VERSION "dbc-export 1 2026.26.6.5"

NS_ :

BS_:

BU_: ADSP APB APP APS APSB BB BMS CC CMP CMPD CP DAS DI DIF DIR DPB EPAS3P EPAS3S EPASTP EPASTS EPBL EPBR ESP EVSE FC GTW HCML HCMR HVP IBST ICR IDB LS OCS1P PARK PCS PCS2 PM PMF PMR PNCD PTC RADC RCM RCM2 RCM3 RCU SCCM SCM SCS SDCR TAS TCU TCU2 TPMS TRCM UI UIS UMC USM V2G VC VCBATT VCBATT0 VCBATT1 VCBATT2 VCCC VCFRONT VCFRONT1 VCFRONT2 VCLEFT VCRIGHT VCSEAT2L VCSEAT2R VCSEC VEH

BO_ 1486 PARK_alertLog: 8 PARK
 SG_ PARK_alertID M : 0|7@1+ (1,0) [0|127] "" Vector__XXX
 SG_ PARK_alertState : 15|1@1+ (1,0) [0|1] "" Vector__XXX
 SG_ PARK_sw001_sensorTemperature m1 : 16|16@1+ (0.1,-40) [-40|6513.5] "" Vector__XXX
 SG_ PARK_sw002_membraneDisconct m2 : 16|1@1+ (1,0) [0|1] "" Vector__XXX
 SG_ PARK_sw002_dampResistorFail m2 : 17|1@1+ (1,0) [0|1] "" Vector__XXX
 SG_ PARK_sw002_resonanceDrift m2 : 18|1@1+ (1,0) [0|1] "" Vector__XXX
 SG_ PARK_sw002_sensorCRC m2 : 19|1@1+ (1,0) [0|1] "" Vector__XXX
 SG_ PARK_sw002_recieveFailure m2 : 20|1@1+ (1,0) [0|1] "" Vector__XXX
 SG_ PARK_sw002_diagnosticTransferErr m2 : 21|1@1+ (1,0) [0|1] "" Vector__XXX
 SG_ PARK_sw003_linError m3 : 16|1@1+ (1,0) [0|1] "" Vector__XXX
 SG_ PARK_sw003_linBusError m3 : 17|1@1+ (1,0) [0|1] "" Vector__XXX
 SG_ PARK_sw003_linFrameCountError m3 : 18|1@1+ (1,0) [0|1] "" Vector__XXX
 SG_ PARK_sw004_reverbPeriod m4 : 16|16@1+ (1,0) [0|65535] "" Vector__XXX
 SG_ PARK_sw004_reverbTime m4 : 32|16@1+ (1,0) [0|65535] "" Vector__XXX
 SG_ PARK_sw004_highAttenTime m4 : 48|1@1+ (1,0) [0|1] "" Vector__XXX
 SG_ PARK_sw004_closeConstEcho m4 : 49|1@1+ (1,0) [0|1] "" Vector__XXX
 SG_ PARK_sw004_lowAttenTime m4 : 50|1@1+ (1,0) [0|1] "" Vector__XXX
 SG_ PARK_sw004_attenTimeJitter m4 : 51|1@1+ (1,0) [0|1] "" Vector__XXX
 SG_ PARK_sw004_reverbFreqJitter m4 : 52|1@1+ (1,0) [0|1] "" Vector__XXX
 SG_ PARK_sw006_sensorTemperature m6 : 16|16@1+ (0.1,-40) [-40|6513.5] "" Vector__XXX
 SG_ PARK_sw007_membraneDisconct m7 : 16|1@1+ (1,0) [0|1] "" Vector__XXX
 SG_ PARK_sw007_dampResistorFail m7 : 17|1@1+ (1,0) [0|1] "" Vector__XXX
 SG_ PARK_sw007_resonanceDrift m7 : 18|1@1+ (1,0) [0|1] "" Vector__XXX
 SG_ PARK_sw007_sensorCRC m7 : 19|1@1+ (1,0) [0|1] "" Vector__XXX
 SG_ PARK_sw007_recieveFailure m7 : 20|1@1+ (1,0) [0|1] "" Vector__XXX
 SG_ PARK_sw007_diagnosticTransferErr m7 : 21|1@1+ (1,0) [0|1] "" Vector__XXX
 SG_ PARK_sw008_linError m8 : 16|1@1+ (1,0) [0|1] "" Vector__XXX
 SG_ PARK_sw008_linBusError m8 : 17|1@1+ (1,0) [0|1] "" Vector__XXX
 SG_ PARK_sw008_linFrameCountError m8 : 18|1@1+ (1,0) [0|1] "" Vector__XXX
 SG_ PARK_sw009_reverbPeriod m9 : 16|16@1+ (1,0) [0|65535] "" Vector__XXX
 SG_ PARK_sw009_reverbTime m9 : 32|16@1+ (1,0) [0|65535] "" Vector__XXX
 SG_ PARK_sw009_highAttenTime m9 : 48|1@1+ (1,0) [0|1] "" Vector__XXX
 SG_ PARK_sw009_closeConstEcho m9 : 49|1@1+ (1,0) [0|1] "" Vector__XXX
 SG_ PARK_sw009_lowAttenTime m9 : 50|1@1+ (1,0) [0|1] "" Vector__XXX
 SG_ PARK_sw009_attenTimeJitter m9 : 51|1@1+ (1,0) [0|1] "" Vector__XXX
 SG_ PARK_sw009_reverbFreqJitter m9 : 52|1@1+ (1,0) [0|1] "" Vector__XXX
 SG_ PARK_sw011_sensorTemperature m11 : 16|16@1+ (0.1,-40) [-40|6513.5] "" Vector__XXX
 SG_ PARK_sw012_membraneDisconct m12 : 16|1@1+ (1,0) [0|1] "" Vector__XXX
 SG_ PARK_sw012_dampResistorFail m12 : 17|1@1+ (1,0) [0|1] "" Vector__XXX
 SG_ PARK_sw012_resonanceDrift m12 : 18|1@1+ (1,0) [0|1] "" Vector__XXX
 SG_ PARK_sw012_sensorCRC m12 : 19|1@1+ (1,0) [0|1] "" Vector__XXX
 SG_ PARK_sw012_recieveFailure m12 : 20|1@1+ (1,0) [0|1] "" Vector__XXX
 SG_ PARK_sw012_diagnosticTransferErr m12 : 21|1@1+ (1,0) [0|1] "" Vector__XXX
 SG_ PARK_sw013_linError m13 : 16|1@1+ (1,0) [0|1] "" Vector__XXX
 SG_ PARK_sw013_linBusError m13 : 17|1@1+ (1,0) [0|1] "" Vector__XXX
 SG_ PARK_sw013_linFrameCountError m13 : 18|1@1+ (1,0) [0|1] "" Vector__XXX
 SG_ PARK_sw014_reverbPeriod m14 : 16|16@1+ (1,0) [0|65535] "" Vector__XXX
 SG_ PARK_sw014_reverbTime m14 : 32|16@1+ (1,0) [0|65535] "" Vector__XXX
 SG_ PARK_sw014_highAttenTime m14 : 48|1@1+ (1,0) [0|1] "" Vector__XXX
 SG_ PARK_sw014_closeConstEcho m14 : 49|1@1+ (1,0) [0|1] "" Vector__XXX
 SG_ PARK_sw014_lowAttenTime m14 : 50|1@1+ (1,0) [0|1] "" Vector__XXX
 SG_ PARK_sw014_attenTimeJitter m14 : 51|1@1+ (1,0) [0|1] "" Vector__XXX
 SG_ PARK_sw014_reverbFreqJitter m14 : 52|1@1+ (1,0) [0|1] "" Vector__XXX
 SG_ PARK_sw016_sensorTemperature m16 : 16|16@1+ (0.1,-40) [-40|6513.5] "" Vector__XXX
 SG_ PARK_sw017_membraneDisconct m17 : 16|1@1+ (1,0) [0|1] "" Vector__XXX
 SG_ PARK_sw017_dampResistorFail m17 : 17|1@1+ (1,0) [0|1] "" Vector__XXX
 SG_ PARK_sw017_resonanceDrift m17 : 18|1@1+ (1,0) [0|1] "" Vector__XXX
 SG_ PARK_sw017_sensorCRC m17 : 19|1@1+ (1,0) [0|1] "" Vector__XXX
 SG_ PARK_sw017_recieveFailure m17 : 20|1@1+ (1,0) [0|1] "" Vector__XXX
 SG_ PARK_sw017_diagnosticTransferErr m17 : 21|1@1+ (1,0) [0|1] "" Vector__XXX
 SG_ PARK_sw018_linError m18 : 16|1@1+ (1,0) [0|1] "" Vector__XXX
 SG_ PARK_sw018_linBusError m18 : 17|1@1+ (1,0) [0|1] "" Vector__XXX
 SG_ PARK_sw018_linFrameCountError m18 : 18|1@1+ (1,0) [0|1] "" Vector__XXX
 SG_ PARK_sw019_reverbPeriod m19 : 16|16@1+ (1,0) [0|65535] "" Vector__XXX
 SG_ PARK_sw019_reverbTime m19 : 32|16@1+ (1,0) [0|65535] "" Vector__XXX
 SG_ PARK_sw019_highAttenTime m19 : 48|1@1+ (1,0) [0|1] "" Vector__XXX
 SG_ PARK_sw019_closeConstEcho m19 : 49|1@1+ (1,0) [0|1] "" Vector__XXX
 SG_ PARK_sw019_lowAttenTime m19 : 50|1@1+ (1,0) [0|1] "" Vector__XXX
 SG_ PARK_sw019_attenTimeJitter m19 : 51|1@1+ (1,0) [0|1] "" Vector__XXX
 SG_ PARK_sw019_reverbFreqJitter m19 : 52|1@1+ (1,0) [0|1] "" Vector__XXX
 SG_ PARK_sw021_sensorTemperature m21 : 16|16@1+ (0.1,-40) [-40|6513.5] "" Vector__XXX
 SG_ PARK_sw022_membraneDisconct m22 : 16|1@1+ (1,0) [0|1] "" Vector__XXX
 SG_ PARK_sw022_dampResistorFail m22 : 17|1@1+ (1,0) [0|1] "" Vector__XXX
 SG_ PARK_sw022_resonanceDrift m22 : 18|1@1+ (1,0) [0|1] "" Vector__XXX
 SG_ PARK_sw022_sensorCRC m22 : 19|1@1+ (1,0) [0|1] "" Vector__XXX
 SG_ PARK_sw022_recieveFailure m22 : 20|1@1+ (1,0) [0|1] "" Vector__XXX
 SG_ PARK_sw022_diagnosticTransferErr m22 : 21|1@1+ (1,0) [0|1] "" Vector__XXX
 SG_ PARK_sw023_linError m23 : 16|1@1+ (1,0) [0|1] "" Vector__XXX
 SG_ PARK_sw023_linBusError m23 : 17|1@1+ (1,0) [0|1] "" Vector__XXX
 SG_ PARK_sw023_linFrameCountError m23 : 18|1@1+ (1,0) [0|1] "" Vector__XXX
 SG_ PARK_sw024_reverbPeriod m24 : 16|16@1+ (1,0) [0|65535] "" Vector__XXX
 SG_ PARK_sw024_reverbTime m24 : 32|16@1+ (1,0) [0|65535] "" Vector__XXX
 SG_ PARK_sw024_highAttenTime m24 : 48|1@1+ (1,0) [0|1] "" Vector__XXX
 SG_ PARK_sw024_closeConstEcho m24 : 49|1@1+ (1,0) [0|1] "" Vector__XXX
 SG_ PARK_sw024_lowAttenTime m24 : 50|1@1+ (1,0) [0|1] "" Vector__XXX
 SG_ PARK_sw024_attenTimeJitter m24 : 51|1@1+ (1,0) [0|1] "" Vector__XXX
 SG_ PARK_sw024_reverbFreqJitter m24 : 52|1@1+ (1,0) [0|1] "" Vector__XXX
 SG_ PARK_sw026_sensorTemperature m26 : 16|16@1+ (0.1,-40) [-40|6513.5] "" Vector__XXX
 SG_ PARK_sw027_membraneDisconct m27 : 16|1@1+ (1,0) [0|1] "" Vector__XXX
 SG_ PARK_sw027_dampResistorFail m27 : 17|1@1+ (1,0) [0|1] "" Vector__XXX
 SG_ PARK_sw027_resonanceDrift m27 : 18|1@1+ (1,0) [0|1] "" Vector__XXX
 SG_ PARK_sw027_sensorCRC m27 : 19|1@1+ (1,0) [0|1] "" Vector__XXX
 SG_ PARK_sw027_recieveFailure m27 : 20|1@1+ (1,0) [0|1] "" Vector__XXX
 SG_ PARK_sw027_diagnosticTransferErr m27 : 21|1@1+ (1,0) [0|1] "" Vector__XXX
 SG_ PARK_sw028_linError m28 : 16|1@1+ (1,0) [0|1] "" Vector__XXX
 SG_ PARK_sw028_linBusError m28 : 17|1@1+ (1,0) [0|1] "" Vector__XXX
 SG_ PARK_sw028_linFrameCountError m28 : 18|1@1+ (1,0) [0|1] "" Vector__XXX
 SG_ PARK_sw029_reverbPeriod m29 : 16|16@1+ (1,0) [0|65535] "" Vector__XXX
 SG_ PARK_sw029_reverbTime m29 : 32|16@1+ (1,0) [0|65535] "" Vector__XXX
 SG_ PARK_sw029_highAttenTime m29 : 48|1@1+ (1,0) [0|1] "" Vector__XXX
 SG_ PARK_sw029_closeConstEcho m29 : 49|1@1+ (1,0) [0|1] "" Vector__XXX
 SG_ PARK_sw029_lowAttenTime m29 : 50|1@1+ (1,0) [0|1] "" Vector__XXX
 SG_ PARK_sw029_attenTimeJitter m29 : 51|1@1+ (1,0) [0|1] "" Vector__XXX
 SG_ PARK_sw029_reverbFreqJitter m29 : 52|1@1+ (1,0) [0|1] "" Vector__XXX
 SG_ PARK_sw031_sensorTemperature m31 : 16|16@1+ (0.1,-40) [-40|6513.5] "" Vector__XXX
 SG_ PARK_sw032_membraneDisconct m32 : 16|1@1+ (1,0) [0|1] "" Vector__XXX
 SG_ PARK_sw032_dampResistorFail m32 : 17|1@1+ (1,0) [0|1] "" Vector__XXX
 SG_ PARK_sw032_resonanceDrift m32 : 18|1@1+ (1,0) [0|1] "" Vector__XXX
 SG_ PARK_sw032_sensorCRC m32 : 19|1@1+ (1,0) [0|1] "" Vector__XXX
 SG_ PARK_sw032_recieveFailure m32 : 20|1@1+ (1,0) [0|1] "" Vector__XXX
 SG_ PARK_sw032_diagnosticTransferErr m32 : 21|1@1+ (1,0) [0|1] "" Vector__XXX
 SG_ PARK_sw033_linError m33 : 16|1@1+ (1,0) [0|1] "" Vector__XXX
 SG_ PARK_sw033_linBusError m33 : 17|1@1+ (1,0) [0|1] "" Vector__XXX
 SG_ PARK_sw033_linFrameCountError m33 : 18|1@1+ (1,0) [0|1] "" Vector__XXX
 SG_ PARK_sw034_reverbPeriod m34 : 16|16@1+ (1,0) [0|65535] "" Vector__XXX
 SG_ PARK_sw034_reverbTime m34 : 32|16@1+ (1,0) [0|65535] "" Vector__XXX
 SG_ PARK_sw034_highAttenTime m34 : 48|1@1+ (1,0) [0|1] "" Vector__XXX
 SG_ PARK_sw034_closeConstEcho m34 : 49|1@1+ (1,0) [0|1] "" Vector__XXX
 SG_ PARK_sw034_lowAttenTime m34 : 50|1@1+ (1,0) [0|1] "" Vector__XXX
 SG_ PARK_sw034_attenTimeJitter m34 : 51|1@1+ (1,0) [0|1] "" Vector__XXX
 SG_ PARK_sw034_reverbFreqJitter m34 : 52|1@1+ (1,0) [0|1] "" Vector__XXX
 SG_ PARK_sw036_sensorTemperature m36 : 16|16@1+ (0.1,-40) [-40|6513.5] "" Vector__XXX
 SG_ PARK_sw037_membraneDisconct m37 : 16|1@1+ (1,0) [0|1] "" Vector__XXX
 SG_ PARK_sw037_dampResistorFail m37 : 17|1@1+ (1,0) [0|1] "" Vector__XXX
 SG_ PARK_sw037_resonanceDrift m37 : 18|1@1+ (1,0) [0|1] "" Vector__XXX
 SG_ PARK_sw037_sensorCRC m37 : 19|1@1+ (1,0) [0|1] "" Vector__XXX
 SG_ PARK_sw037_recieveFailure m37 : 20|1@1+ (1,0) [0|1] "" Vector__XXX
 SG_ PARK_sw037_diagnosticTransferErr m37 : 21|1@1+ (1,0) [0|1] "" Vector__XXX
 SG_ PARK_sw038_linError m38 : 16|1@1+ (1,0) [0|1] "" Vector__XXX
 SG_ PARK_sw038_linBusError m38 : 17|1@1+ (1,0) [0|1] "" Vector__XXX
 SG_ PARK_sw038_linFrameCountError m38 : 18|1@1+ (1,0) [0|1] "" Vector__XXX
 SG_ PARK_sw039_reverbPeriod m39 : 16|16@1+ (1,0) [0|65535] "" Vector__XXX
 SG_ PARK_sw039_reverbTime m39 : 32|16@1+ (1,0) [0|65535] "" Vector__XXX
 SG_ PARK_sw039_highAttenTime m39 : 48|1@1+ (1,0) [0|1] "" Vector__XXX
 SG_ PARK_sw039_closeConstEcho m39 : 49|1@1+ (1,0) [0|1] "" Vector__XXX
 SG_ PARK_sw039_lowAttenTime m39 : 50|1@1+ (1,0) [0|1] "" Vector__XXX
 SG_ PARK_sw039_attenTimeJitter m39 : 51|1@1+ (1,0) [0|1] "" Vector__XXX
 SG_ PARK_sw039_reverbFreqJitter m39 : 52|1@1+ (1,0) [0|1] "" Vector__XXX
 SG_ PARK_sw041_sensorTemperature m41 : 16|16@1+ (0.1,-40) [-40|6513.5] "" Vector__XXX
 SG_ PARK_sw042_membraneDisconct m42 : 16|1@1+ (1,0) [0|1] "" Vector__XXX
 SG_ PARK_sw042_dampResistorFail m42 : 17|1@1+ (1,0) [0|1] "" Vector__XXX
 SG_ PARK_sw042_resonanceDrift m42 : 18|1@1+ (1,0) [0|1] "" Vector__XXX
 SG_ PARK_sw042_sensorCRC m42 : 19|1@1+ (1,0) [0|1] "" Vector__XXX
 SG_ PARK_sw042_recieveFailure m42 : 20|1@1+ (1,0) [0|1] "" Vector__XXX
 SG_ PARK_sw042_diagnosticTransferErr m42 : 21|1@1+ (1,0) [0|1] "" Vector__XXX
 SG_ PARK_sw043_linError m43 : 16|1@1+ (1,0) [0|1] "" Vector__XXX
 SG_ PARK_sw043_linBusError m43 : 17|1@1+ (1,0) [0|1] "" Vector__XXX
 SG_ PARK_sw043_linFrameCountError m43 : 18|1@1+ (1,0) [0|1] "" Vector__XXX
 SG_ PARK_sw044_reverbPeriod m44 : 16|16@1+ (1,0) [0|65535] "" Vector__XXX
 SG_ PARK_sw044_reverbTime m44 : 32|16@1+ (1,0) [0|65535] "" Vector__XXX
 SG_ PARK_sw044_highAttenTime m44 : 48|1@1+ (1,0) [0|1] "" Vector__XXX
 SG_ PARK_sw044_closeConstEcho m44 : 49|1@1+ (1,0) [0|1] "" Vector__XXX
 SG_ PARK_sw044_lowAttenTime m44 : 50|1@1+ (1,0) [0|1] "" Vector__XXX
 SG_ PARK_sw044_attenTimeJitter m44 : 51|1@1+ (1,0) [0|1] "" Vector__XXX
 SG_ PARK_sw044_reverbFreqJitter m44 : 52|1@1+ (1,0) [0|1] "" Vector__XXX
 SG_ PARK_sw046_sensorTemperature m46 : 16|16@1+ (0.1,-40) [-40|6513.5] "" Vector__XXX
 SG_ PARK_sw047_membraneDisconct m47 : 16|1@1+ (1,0) [0|1] "" Vector__XXX
 SG_ PARK_sw047_dampResistorFail m47 : 17|1@1+ (1,0) [0|1] "" Vector__XXX
 SG_ PARK_sw047_resonanceDrift m47 : 18|1@1+ (1,0) [0|1] "" Vector__XXX
 SG_ PARK_sw047_sensorCRC m47 : 19|1@1+ (1,0) [0|1] "" Vector__XXX
 SG_ PARK_sw047_recieveFailure m47 : 20|1@1+ (1,0) [0|1] "" Vector__XXX
 SG_ PARK_sw047_diagnosticTransferErr m47 : 21|1@1+ (1,0) [0|1] "" Vector__XXX
 SG_ PARK_sw048_linError m48 : 16|1@1+ (1,0) [0|1] "" Vector__XXX
 SG_ PARK_sw048_linBusError m48 : 17|1@1+ (1,0) [0|1] "" Vector__XXX
 SG_ PARK_sw048_linFrameCountError m48 : 18|1@1+ (1,0) [0|1] "" Vector__XXX
 SG_ PARK_sw049_reverbPeriod m49 : 16|16@1+ (1,0) [0|65535] "" Vector__XXX
 SG_ PARK_sw049_reverbTime m49 : 32|16@1+ (1,0) [0|65535] "" Vector__XXX
 SG_ PARK_sw049_highAttenTime m49 : 48|1@1+ (1,0) [0|1] "" Vector__XXX
 SG_ PARK_sw049_closeConstEcho m49 : 49|1@1+ (1,0) [0|1] "" Vector__XXX
 SG_ PARK_sw049_lowAttenTime m49 : 50|1@1+ (1,0) [0|1] "" Vector__XXX
 SG_ PARK_sw049_attenTimeJitter m49 : 51|1@1+ (1,0) [0|1] "" Vector__XXX
 SG_ PARK_sw049_reverbFreqJitter m49 : 52|1@1+ (1,0) [0|1] "" Vector__XXX
 SG_ PARK_sw051_sensorTemperature m51 : 16|16@1+ (0.1,-40) [-40|6513.5] "" Vector__XXX
 SG_ PARK_sw052_membraneDisconct m52 : 16|1@1+ (1,0) [0|1] "" Vector__XXX
 SG_ PARK_sw052_dampResistorFail m52 : 17|1@1+ (1,0) [0|1] "" Vector__XXX
 SG_ PARK_sw052_resonanceDrift m52 : 18|1@1+ (1,0) [0|1] "" Vector__XXX
 SG_ PARK_sw052_sensorCRC m52 : 19|1@1+ (1,0) [0|1] "" Vector__XXX
 SG_ PARK_sw052_recieveFailure m52 : 20|1@1+ (1,0) [0|1] "" Vector__XXX
 SG_ PARK_sw052_diagnosticTransferErr m52 : 21|1@1+ (1,0) [0|1] "" Vector__XXX
 SG_ PARK_sw053_linError m53 : 16|1@1+ (1,0) [0|1] "" Vector__XXX
 SG_ PARK_sw053_linBusError m53 : 17|1@1+ (1,0) [0|1] "" Vector__XXX
 SG_ PARK_sw053_linFrameCountError m53 : 18|1@1+ (1,0) [0|1] "" Vector__XXX
 SG_ PARK_sw054_reverbPeriod m54 : 16|16@1+ (1,0) [0|65535] "" Vector__XXX
 SG_ PARK_sw054_reverbTime m54 : 32|16@1+ (1,0) [0|65535] "" Vector__XXX
 SG_ PARK_sw054_highAttenTime m54 : 48|1@1+ (1,0) [0|1] "" Vector__XXX
 SG_ PARK_sw054_closeConstEcho m54 : 49|1@1+ (1,0) [0|1] "" Vector__XXX
 SG_ PARK_sw054_lowAttenTime m54 : 50|1@1+ (1,0) [0|1] "" Vector__XXX
 SG_ PARK_sw054_attenTimeJitter m54 : 51|1@1+ (1,0) [0|1] "" Vector__XXX
 SG_ PARK_sw054_reverbFreqJitter m54 : 52|1@1+ (1,0) [0|1] "" Vector__XXX
 SG_ PARK_sw056_sensorTemperature m56 : 16|16@1+ (0.1,-40) [-40|6513.5] "" Vector__XXX
 SG_ PARK_sw057_membraneDisconct m57 : 16|1@1+ (1,0) [0|1] "" Vector__XXX
 SG_ PARK_sw057_dampResistorFail m57 : 17|1@1+ (1,0) [0|1] "" Vector__XXX
 SG_ PARK_sw057_resonanceDrift m57 : 18|1@1+ (1,0) [0|1] "" Vector__XXX
 SG_ PARK_sw057_sensorCRC m57 : 19|1@1+ (1,0) [0|1] "" Vector__XXX
 SG_ PARK_sw057_recieveFailure m57 : 20|1@1+ (1,0) [0|1] "" Vector__XXX
 SG_ PARK_sw057_diagnosticTransferErr m57 : 21|1@1+ (1,0) [0|1] "" Vector__XXX
 SG_ PARK_sw058_linError m58 : 16|1@1+ (1,0) [0|1] "" Vector__XXX
 SG_ PARK_sw058_linBusError m58 : 17|1@1+ (1,0) [0|1] "" Vector__XXX
 SG_ PARK_sw058_linFrameCountError m58 : 18|1@1+ (1,0) [0|1] "" Vector__XXX
 SG_ PARK_sw059_reverbPeriod m59 : 16|16@1+ (1,0) [0|65535] "" Vector__XXX
 SG_ PARK_sw059_reverbTime m59 : 32|16@1+ (1,0) [0|65535] "" Vector__XXX
 SG_ PARK_sw059_highAttenTime m59 : 48|1@1+ (1,0) [0|1] "" Vector__XXX
 SG_ PARK_sw059_closeConstEcho m59 : 49|1@1+ (1,0) [0|1] "" Vector__XXX
 SG_ PARK_sw059_lowAttenTime m59 : 50|1@1+ (1,0) [0|1] "" Vector__XXX
 SG_ PARK_sw059_attenTimeJitter m59 : 51|1@1+ (1,0) [0|1] "" Vector__XXX
 SG_ PARK_sw059_reverbFreqJitter m59 : 52|1@1+ (1,0) [0|1] "" Vector__XXX
 SG_ PARK_sw061_voltage m61 : 16|16@1+ (0.1,0) [0|6553.5] "" Vector__XXX
 SG_ PARK_sw063_voltage m63 : 16|16@1+ (0.1,0) [0|6553.5] "" Vector__XXX
 SG_ PARK_sw064_faultCode m64 : 16|8@1+ (1,0) [0|255] "" Vector__XXX
 SG_ PARK_sw065_expectedCRC m65 : 16|16@1+ (1,0) [0|65535] "" Vector__XXX
 SG_ PARK_sw065_calculatedCRC m65 : 32|16@1+ (1,0) [0|65535] "" Vector__XXX
 SG_ PARK_sw066_placeHolder m66 : 16|1@1+ (1,0) [0|1] "" Vector__XXX
 SG_ PARK_sw068_placeHolder m68 : 16|1@1+ (1,0) [0|1] "" Vector__XXX
 SG_ PARK_sw069_messageID m69 : 16|16@1+ (1,0) [0|65535] "" Vector__XXX
 SG_ PARK_sw070_messageID m70 : 16|16@1+ (1,0) [0|65535] "" Vector__XXX
 SG_ PARK_sw071_messageID m71 : 16|16@1+ (1,0) [0|65535] "" Vector__XXX
 SG_ PARK_sw072_messageID m72 : 16|16@1+ (1,0) [0|65535] "" Vector__XXX
 SG_ PARK_sw073_messageID m73 : 16|16@1+ (1,0) [0|65535] "" Vector__XXX
 SG_ PARK_sw074_messageID m74 : 16|16@1+ (1,0) [0|65535] "" Vector__XXX
 SG_ PARK_sw075_messageID m75 : 16|16@1+ (1,0) [0|65535] "" Vector__XXX
 SG_ PARK_sw076_messageID m76 : 16|16@1+ (1,0) [0|65535] "" Vector__XXX
 SG_ PARK_sw077_errorExp m77 : 16|8@1+ (1,0) [0|255] "" Vector__XXX
 SG_ PARK_sw077_errorRx m77 : 24|8@1+ (1,0) [0|255] "" Vector__XXX
 SG_ PARK_sw077_messageID m77 : 32|12@1+ (1,0) [0|4095] "" Vector__XXX
 SG_ PARK_sw077_errorType m77 : 44|3@1+ (1,0) [0|7] "" Vector__XXX
 SG_ PARK_sw078_errorExp m78 : 16|8@1+ (1,0) [0|255] "" Vector__XXX
 SG_ PARK_sw078_errorRx m78 : 24|8@1+ (1,0) [0|255] "" Vector__XXX
 SG_ PARK_sw078_messageID m78 : 32|12@1+ (1,0) [0|4095] "" Vector__XXX
 SG_ PARK_sw078_errorType m78 : 44|3@1+ (1,0) [0|7] "" Vector__XXX
 SG_ PARK_sw079_errorExp m79 : 16|8@1+ (1,0) [0|255] "" Vector__XXX
 SG_ PARK_sw079_errorRx m79 : 24|8@1+ (1,0) [0|255] "" Vector__XXX
 SG_ PARK_sw079_messageID m79 : 32|12@1+ (1,0) [0|4095] "" Vector__XXX
 SG_ PARK_sw079_errorType m79 : 44|3@1+ (1,0) [0|7] "" Vector__XXX
 SG_ PARK_sw080_errorExp m80 : 16|8@1+ (1,0) [0|255] "" Vector__XXX
 SG_ PARK_sw080_errorRx m80 : 24|8@1+ (1,0) [0|255] "" Vector__XXX
 SG_ PARK_sw080_messageID m80 : 32|12@1+ (1,0) [0|4095] "" Vector__XXX
 SG_ PARK_sw080_errorType m80 : 44|3@1+ (1,0) [0|7] "" Vector__XXX
 SG_ PARK_sw081_errorExp m81 : 16|8@1+ (1,0) [0|255] "" Vector__XXX
 SG_ PARK_sw081_errorRx m81 : 24|8@1+ (1,0) [0|255] "" Vector__XXX
 SG_ PARK_sw081_messageID m81 : 32|12@1+ (1,0) [0|4095] "" Vector__XXX
 SG_ PARK_sw081_errorType m81 : 44|3@1+ (1,0) [0|7] "" Vector__XXX
 SG_ PARK_sw082_errorExp m82 : 16|8@1+ (1,0) [0|255] "" Vector__XXX
 SG_ PARK_sw082_errorRx m82 : 24|8@1+ (1,0) [0|255] "" Vector__XXX
 SG_ PARK_sw082_messageID m82 : 32|12@1+ (1,0) [0|4095] "" Vector__XXX
 SG_ PARK_sw082_errorType m82 : 44|3@1+ (1,0) [0|7] "" Vector__XXX
 SG_ PARK_sw083_errorExp m83 : 16|8@1+ (1,0) [0|255] "" Vector__XXX
 SG_ PARK_sw083_errorRx m83 : 24|8@1+ (1,0) [0|255] "" Vector__XXX
 SG_ PARK_sw083_messageID m83 : 32|12@1+ (1,0) [0|4095] "" Vector__XXX
 SG_ PARK_sw083_errorType m83 : 44|3@1+ (1,0) [0|7] "" Vector__XXX
 SG_ PARK_sw084_errorExp m84 : 16|8@1+ (1,0) [0|255] "" Vector__XXX
 SG_ PARK_sw084_errorRx m84 : 24|8@1+ (1,0) [0|255] "" Vector__XXX
 SG_ PARK_sw084_messageID m84 : 32|12@1+ (1,0) [0|4095] "" Vector__XXX
 SG_ PARK_sw084_errorType m84 : 44|3@1+ (1,0) [0|7] "" Vector__XXX
 SG_ PARK_sw086_writeRetryCounter m86 : 16|8@1+ (1,0) [0|255] "" Vector__XXX
 SG_ PARK_sw086_readRetryCounter m86 : 24|8@1+ (1,0) [0|255] "" Vector__XXX
 SG_ PARK_sw086_currentErrorCode m86 : 32|8@1+ (1,0) [0|255] "" Vector__XXX
 SG_ PARK_sw087_s1_sensorType m87 : 16|2@1+ (1,0) [0|3] "" Vector__XXX
 SG_ PARK_sw087_s2_sensorType m87 : 18|2@1+ (1,0) [0|3] "" Vector__XXX
 SG_ PARK_sw087_s3_sensorType m87 : 20|2@1+ (1,0) [0|3] "" Vector__XXX
 SG_ PARK_sw087_s4_sensorType m87 : 22|2@1+ (1,0) [0|3] "" Vector__XXX
 SG_ PARK_sw087_s5_sensorType m87 : 24|2@1+ (1,0) [0|3] "" Vector__XXX
 SG_ PARK_sw087_s6_sensorType m87 : 26|2@1+ (1,0) [0|3] "" Vector__XXX
 SG_ PARK_sw087_s7_sensorType m87 : 28|2@1+ (1,0) [0|3] "" Vector__XXX
 SG_ PARK_sw087_s8_sensorType m87 : 30|2@1+ (1,0) [0|3] "" Vector__XXX
 SG_ PARK_sw087_s9_sensorType m87 : 32|2@1+ (1,0) [0|3] "" Vector__XXX
 SG_ PARK_sw087_s10_sensorType m87 : 34|2@1+ (1,0) [0|3] "" Vector__XXX
 SG_ PARK_sw087_s11_sensorType m87 : 36|2@1+ (1,0) [0|3] "" Vector__XXX
 SG_ PARK_sw087_s12_sensorType m87 : 38|2@1+ (1,0) [0|3] "" Vector__XXX

BO_ 806 PARK_info: 8 PARK
 SG_ PARK_infoIndex M : 0|8@1+ (1,0) [0|255] "" Vector__XXX
 SG_ PARK_infoBuildType m10 : 8|8@1+ (1,0) [0|255] "" Vector__XXX
 SG_ PARK_infoComponentID m10 : 48|16@1+ (1,0) [0|65535] "" Vector__XXX
 SG_ PARK_infoPcbaID m11 : 16|8@1+ (1,0) [0|255] "" Vector__XXX
 SG_ PARK_infoAssemblyID m11 : 24|8@1+ (1,0) [0|255] "" Vector__XXX
 SG_ PARK_infoUsageID m11 : 32|16@1+ (1,0) [0|65535] "" Vector__XXX
 SG_ PARK_infoApplicationCRC m13 : 32|32@1+ (1,0) [0|4294967295] "" Vector__XXX
 SG_ PARK_infoBootUdsProtoVersion m20 : 8|8@1+ (1,0) [0|255] "" Vector__XXX
 SG_ PARK_infoBootloaderCRC m20 : 32|32@1+ (1,0) [0|4294967295] "" Vector__XXX

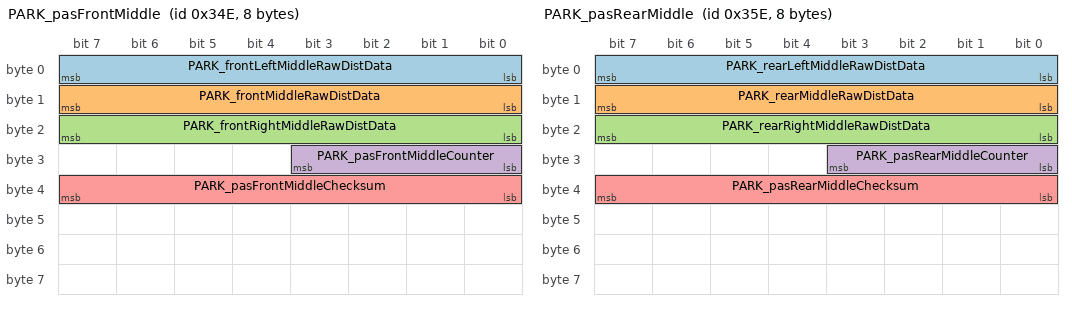
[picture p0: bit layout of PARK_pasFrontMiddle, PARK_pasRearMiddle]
BO_ 846 PARK_pasFrontMiddle: 8 PARK
 SG_ PARK_frontLeftMiddleRawDistData : 0|8@1+ (1,0) [0|255] "cm" Vector__XXX
 SG_ PARK_frontMiddleRawDistData : 8|8@1+ (1,0) [0|255] "cm" Vector__XXX
 SG_ PARK_frontRightMiddleRawDistData : 16|8@1+ (1,0) [0|255] "cm" Vector__XXX
 SG_ PARK_pasFrontMiddleCounter : 24|4@1+ (1,0) [0|15] "" Vector__XXX
 SG_ PARK_pasFrontMiddleChecksum : 32|8@1+ (1,0) [0|255] "" Vector__XXX

BO_ 862 PARK_pasRearMiddle: 8 PARK
 SG_ PARK_rearLeftMiddleRawDistData : 0|8@1+ (1,0) [0|255] "cm" Vector__XXX
 SG_ PARK_rearMiddleRawDistData : 8|8@1+ (1,0) [0|255] "cm" Vector__XXX
 SG_ PARK_rearRightMiddleRawDistData : 16|8@1+ (1,0) [0|255] "cm" Vector__XXX
 SG_ PARK_pasRearMiddleCounter : 24|4@1+ (1,0) [0|15] "" Vector__XXX
 SG_ PARK_pasRearMiddleChecksum : 32|8@1+ (1,0) [0|255] "" Vector__XXX

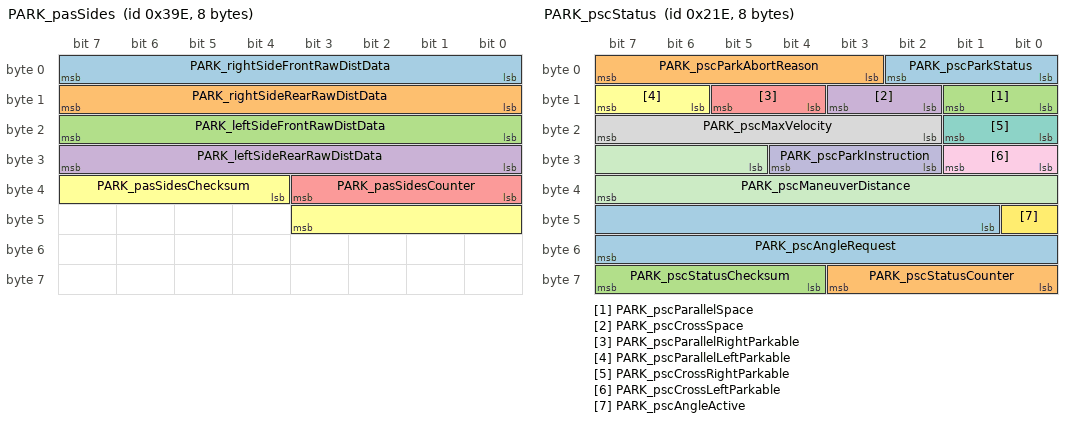
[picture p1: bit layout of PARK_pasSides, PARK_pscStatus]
BO_ 926 PARK_pasSides: 8 PARK
 SG_ PARK_rightSideFrontRawDistData : 0|8@1+ (1,0) [0|255] "cm" Vector__XXX
 SG_ PARK_rightSideRearRawDistData : 8|8@1+ (1,0) [0|255] "cm" Vector__XXX
 SG_ PARK_leftSideFrontRawDistData : 16|8@1+ (1,0) [0|255] "cm" Vector__XXX
 SG_ PARK_leftSideRearRawDistData : 24|8@1+ (1,0) [0|255] "cm" Vector__XXX
 SG_ PARK_pasSidesCounter : 32|4@1+ (1,0) [0|15] "" Vector__XXX
 SG_ PARK_pasSidesChecksum : 36|8@1+ (1,0) [0|255] "" Vector__XXX

BO_ 606 PARK_pscEnvSlot: 8 PARK
 SG_ PARK_pscEnvSlotType M : 0|2@1+ (1,0) [0|3] "" Vector__XXX
 SG_ PARK_pscLeftParallelObj1X m0 : 3|11@1+ (2,-2048) [-2048|2046] "cm" Vector__XXX
 SG_ PARK_pscLeftParallelObj1Y m0 : 14|11@1+ (2,-2048) [-2048|2046] "cm" Vector__XXX
 SG_ PARK_pscLeftParallelObj1Alpha m0 : 25|7@1+ (2,-128) [-128|126] "deg" Vector__XXX
 SG_ PARK_pscLeftParallelObj2Y m0 : 35|11@1+ (2,-2048) [-2048|2046] "cm" Vector__XXX
 SG_ PARK_pscLeftParallelObj2X m0 : 46|11@1+ (2,-2048) [-2048|2046] "cm" Vector__XXX
 SG_ PARK_pscLeftParallelObj2Alpha m0 : 57|7@1+ (2,-128) [-128|126] "deg" Vector__XXX
 SG_ PARK_pscLeftCrossObj1X m1 : 3|11@1+ (2,-2048) [-2048|2046] "cm" Vector__XXX
 SG_ PARK_pscLeftCrossObj1Y m1 : 14|11@1+ (2,-2048) [-2048|2046] "cm" Vector__XXX
 SG_ PARK_pscLeftCrossObj1Alpha m1 : 25|7@1+ (2,-128) [-128|126] "deg" Vector__XXX
 SG_ PARK_pscLeftCrossObj2Y m1 : 35|11@1+ (2,-2048) [-2048|2046] "cm" Vector__XXX
 SG_ PARK_pscLeftCrossObj2X m1 : 46|11@1+ (2,-2048) [-2048|2046] "cm" Vector__XXX
 SG_ PARK_pscLeftCrossObj2Alpha m1 : 57|7@1+ (2,-128) [-128|126] "deg" Vector__XXX
 SG_ PARK_pscRightParallelObj1X m2 : 3|11@1+ (2,-2048) [-2048|2046] "cm" Vector__XXX
 SG_ PARK_pscRightParallelObj1Y m2 : 14|11@1+ (2,-2048) [-2048|2046] "cm" Vector__XXX
 SG_ PARK_pscRightParallelObj1Alpha m2 : 25|7@1+ (2,-128) [-128|126] "deg" Vector__XXX
 SG_ PARK_pscRightParallelObj2Y m2 : 35|11@1+ (2,-2048) [-2048|2046] "cm" Vector__XXX
 SG_ PARK_pscRightParallelObj2X m2 : 46|11@1+ (2,-2048) [-2048|2046] "cm" Vector__XXX
 SG_ PARK_pscRightParallelObj2Alpha m2 : 57|7@1+ (2,-128) [-128|126] "deg" Vector__XXX
 SG_ PARK_pscRightCrossObj1X m3 : 3|11@1+ (2,-2048) [-2048|2046] "cm" Vector__XXX
 SG_ PARK_pscRightCrossObj1Y m3 : 14|11@1+ (2,-2048) [-2048|2046] "cm" Vector__XXX
 SG_ PARK_pscRightCrossObj1Alpha m3 : 25|7@1+ (2,-128) [-128|126] "deg" Vector__XXX
 SG_ PARK_pscRightCrossObj2Y m3 : 35|11@1+ (2,-2048) [-2048|2046] "cm" Vector__XXX
 SG_ PARK_pscRightCrossObj2X m3 : 46|11@1+ (2,-2048) [-2048|2046] "cm" Vector__XXX
 SG_ PARK_pscRightCrossObj2Alpha m3 : 57|7@1+ (2,-128) [-128|126] "deg" Vector__XXX

BO_ 542 PARK_pscStatus: 8 PARK
 SG_ PARK_pscParkStatus : 0|3@1+ (1,0) [0|7] "" Vector__XXX
 SG_ PARK_pscParkAbortReason : 3|5@1+ (1,0) [0|31] "" Vector__XXX
 SG_ PARK_pscParallelSpace : 8|2@1+ (1,0) [0|3] "" Vector__XXX
 SG_ PARK_pscCrossSpace : 10|2@1+ (1,0) [0|3] "" Vector__XXX
 SG_ PARK_pscParallelRightParkable : 12|2@1+ (1,0) [0|3] "" Vector__XXX
 SG_ PARK_pscParallelLeftParkable : 14|2@1+ (1,0) [0|3] "" Vector__XXX
 SG_ PARK_pscCrossRightParkable : 16|2@1+ (1,0) [0|3] "" Vector__XXX
 SG_ PARK_pscMaxVelocity : 18|6@1+ (0.1,0) [0|6.3] "kph" Vector__XXX
 SG_ PARK_pscCrossLeftParkable : 24|2@1+ (1,0) [0|3] "" Vector__XXX
 SG_ PARK_pscParkInstruction : 26|3@1+ (1,0) [0|7] "" Vector__XXX
 SG_ PARK_pscManeuverDistance : 29|11@1+ (1,0) [0|2047] "cm" Vector__XXX
 SG_ PARK_pscAngleActive : 40|1@1+ (1,0) [0|1] "" Vector__XXX
 SG_ PARK_pscAngleRequest : 41|15@1+ (0.1,-1638.4) [-1638.4|1638.3] "deg" Vector__XXX
 SG_ PARK_pscStatusCounter : 56|4@1+ (1,0) [0|15] "" Vector__XXX
 SG_ PARK_pscStatusChecksum : 60|4@1+ (1,0) [0|15] "" Vector__XXX

BO_ 590 PARK_pscVehSlot: 8 PARK
 SG_ PARK_pscVehSlotType M : 0|2@1+ (1,0) [0|3] "" Vector__XXX
 SG_ PARK_pscLeftParallelVehX m0 : 5|11@1+ (2,-2048) [-2048|2046] "cm" Vector__XXX
 SG_ PARK_pscLeftParallelVehY m0 : 16|11@1+ (2,-2048) [-2048|2046] "cm" Vector__XXX
 SG_ PARK_pscLeftParallelPsi m0 : 32|13@1+ (0.0009765625,0) [0|7.9990234375] "radians" Vector__XXX
 SG_ PARK_pscLeftParallelSizeX m0 : 48|8@1+ (4,0) [0|1020] "cm" Vector__XXX
 SG_ PARK_pscLeftParallelSizeY m0 : 56|8@1+ (4,0) [0|1020] "cm" Vector__XXX
 SG_ PARK_pscLeftCrossVehX m1 : 5|11@1+ (2,-2048) [-2048|2046] "cm" Vector__XXX
 SG_ PARK_pscLeftCrossVehY m1 : 16|11@1+ (2,-2048) [-2048|2046] "cm" Vector__XXX
 SG_ PARK_pscLeftCrossPsi m1 : 32|13@1+ (0.0009765625,0) [0|7.9990234375] "radians" Vector__XXX
 SG_ PARK_pscLeftCrossSizeX m1 : 48|8@1+ (4,0) [0|1020] "cm" Vector__XXX
 SG_ PARK_pscLeftCrossSizeY m1 : 56|8@1+ (4,0) [0|1020] "cm" Vector__XXX
 SG_ PARK_pscRightParallelVehX m2 : 5|11@1+ (2,-2048) [-2048|2046] "cm" Vector__XXX
 SG_ PARK_pscRightParallelVehY m2 : 16|11@1+ (2,-2048) [-2048|2046] "cm" Vector__XXX
 SG_ PARK_pscRightParallelPsi m2 : 32|13@1+ (0.0009765625,0) [0|7.9990234375] "radians" Vector__XXX
 SG_ PARK_pscRightParallelSizeX m2 : 48|8@1+ (4,0) [0|1020] "cm" Vector__XXX
 SG_ PARK_pscRightParallelSizeY m2 : 56|8@1+ (4,0) [0|1020] "cm" Vector__XXX
 SG_ PARK_pscRightCrossVehX m3 : 5|11@1+ (2,-2048) [-2048|2046] "cm" Vector__XXX
 SG_ PARK_pscRightCrossVehY m3 : 16|11@1+ (2,-2048) [-2048|2046] "cm" Vector__XXX
 SG_ PARK_pscRightCrossPsi m3 : 32|13@1+ (0.0009765625,0) [0|7.9990234375] "radians" Vector__XXX
 SG_ PARK_pscRightCrossSizeX m3 : 48|8@1+ (4,0) [0|1020] "cm" Vector__XXX
 SG_ PARK_pscRightCrossSizeY m3 : 56|8@1+ (4,0) [0|1020] "cm" Vector__XXX

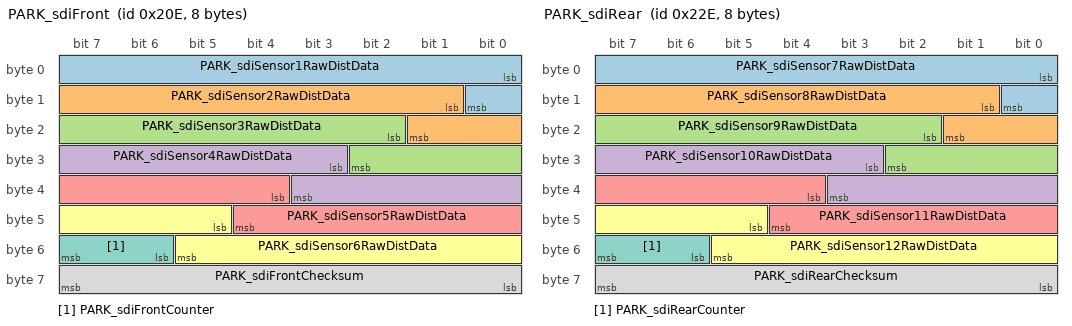
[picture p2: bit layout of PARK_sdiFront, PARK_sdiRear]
BO_ 526 PARK_sdiFront: 8 PARK
 SG_ PARK_sdiSensor1RawDistData : 0|9@1+ (1,0) [0|511] "cm" Vector__XXX
 SG_ PARK_sdiSensor2RawDistData : 9|9@1+ (1,0) [0|511] "cm" Vector__XXX
 SG_ PARK_sdiSensor3RawDistData : 18|9@1+ (1,0) [0|511] "cm" Vector__XXX
 SG_ PARK_sdiSensor4RawDistData : 27|9@1+ (1,0) [0|511] "cm" Vector__XXX
 SG_ PARK_sdiSensor5RawDistData : 36|9@1+ (1,0) [0|511] "cm" Vector__XXX
 SG_ PARK_sdiSensor6RawDistData : 45|9@1+ (1,0) [0|511] "cm" Vector__XXX
 SG_ PARK_sdiFrontCounter : 54|2@1+ (1,0) [0|3] "" Vector__XXX
 SG_ PARK_sdiFrontChecksum : 56|8@1+ (1,0) [0|255] "" Vector__XXX

BO_ 558 PARK_sdiRear: 8 PARK
 SG_ PARK_sdiSensor7RawDistData : 0|9@1+ (1,0) [0|511] "cm" Vector__XXX
 SG_ PARK_sdiSensor8RawDistData : 9|9@1+ (1,0) [0|511] "cm" Vector__XXX
 SG_ PARK_sdiSensor9RawDistData : 18|9@1+ (1,0) [0|511] "cm" Vector__XXX
 SG_ PARK_sdiSensor10RawDistData : 27|9@1+ (1,0) [0|511] "cm" Vector__XXX
 SG_ PARK_sdiSensor11RawDistData : 36|9@1+ (1,0) [0|511] "cm" Vector__XXX
 SG_ PARK_sdiSensor12RawDistData : 45|9@1+ (1,0) [0|511] "cm" Vector__XXX
 SG_ PARK_sdiRearCounter : 54|2@1+ (1,0) [0|3] "" Vector__XXX
 SG_ PARK_sdiRearChecksum : 56|8@1+ (1,0) [0|255] "" Vector__XXX

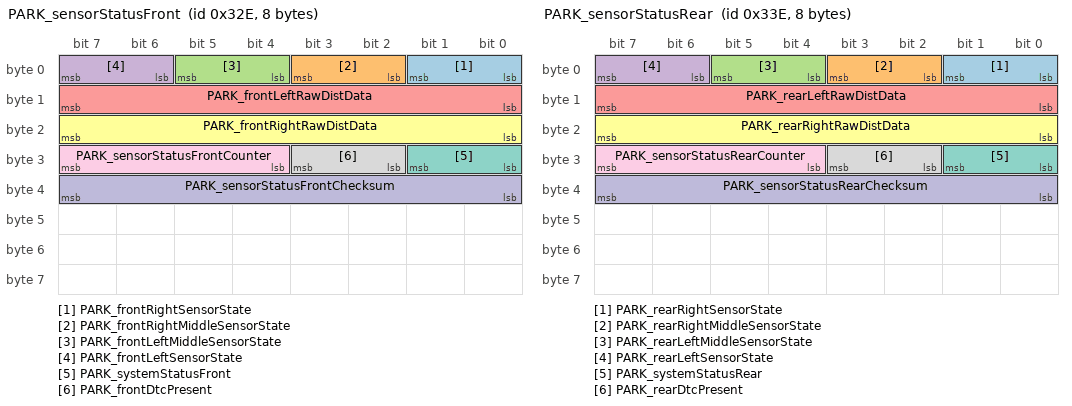
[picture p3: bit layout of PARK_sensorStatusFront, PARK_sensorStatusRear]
BO_ 814 PARK_sensorStatusFront: 8 PARK
 SG_ PARK_frontRightSensorState : 0|2@1+ (1,0) [0|3] "" Vector__XXX
 SG_ PARK_frontRightMiddleSensorState : 2|2@1+ (1,0) [0|3] "" Vector__XXX
 SG_ PARK_frontLeftMiddleSensorState : 4|2@1+ (1,0) [0|3] "" Vector__XXX
 SG_ PARK_frontLeftSensorState : 6|2@1+ (1,0) [0|3] "" Vector__XXX
 SG_ PARK_frontLeftRawDistData : 8|8@1+ (1,0) [0|255] "cm" Vector__XXX
 SG_ PARK_frontRightRawDistData : 16|8@1+ (1,0) [0|255] "cm" Vector__XXX
 SG_ PARK_systemStatusFront : 24|2@1+ (1,0) [0|3] "" Vector__XXX
 SG_ PARK_frontDtcPresent : 26|2@1+ (1,0) [0|3] "" Vector__XXX
 SG_ PARK_sensorStatusFrontCounter : 28|4@1+ (1,0) [0|15] "" Vector__XXX
 SG_ PARK_sensorStatusFrontChecksum : 32|8@1+ (1,0) [0|255] "" Vector__XXX

BO_ 830 PARK_sensorStatusRear: 8 PARK
 SG_ PARK_rearRightSensorState : 0|2@1+ (1,0) [0|3] "" Vector__XXX
 SG_ PARK_rearRightMiddleSensorState : 2|2@1+ (1,0) [0|3] "" Vector__XXX
 SG_ PARK_rearLeftMiddleSensorState : 4|2@1+ (1,0) [0|3] "" Vector__XXX
 SG_ PARK_rearLeftSensorState : 6|2@1+ (1,0) [0|3] "" Vector__XXX
 SG_ PARK_rearLeftRawDistData : 8|8@1+ (1,0) [0|255] "cm" Vector__XXX
 SG_ PARK_rearRightRawDistData : 16|8@1+ (1,0) [0|255] "cm" Vector__XXX
 SG_ PARK_systemStatusRear : 24|2@1+ (1,0) [0|3] "" Vector__XXX
 SG_ PARK_rearDtcPresent : 26|2@1+ (1,0) [0|3] "" Vector__XXX
 SG_ PARK_sensorStatusRearCounter : 28|4@1+ (1,0) [0|15] "" Vector__XXX
 SG_ PARK_sensorStatusRearChecksum : 32|8@1+ (1,0) [0|255] "" Vector__XXX

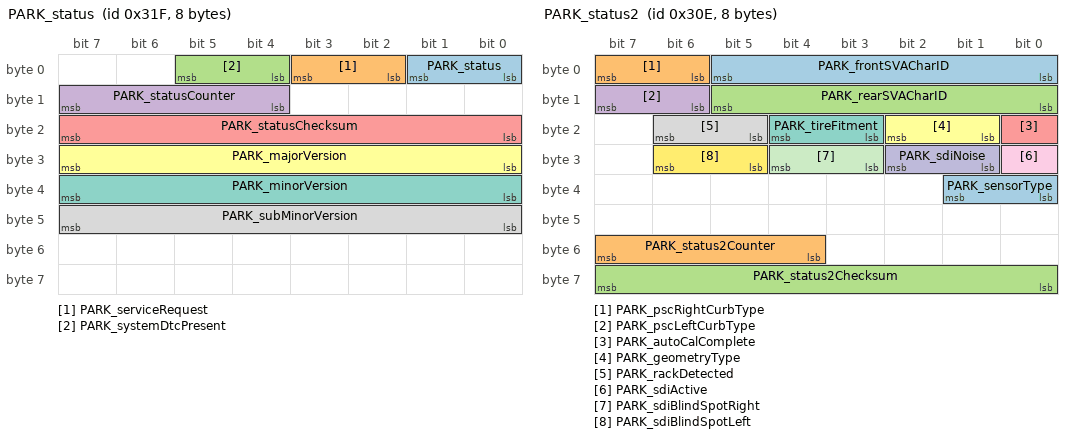
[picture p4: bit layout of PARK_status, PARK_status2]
BO_ 799 PARK_status: 8 PARK
 SG_ PARK_status : 0|2@1+ (1,0) [0|3] "" Vector__XXX
 SG_ PARK_serviceRequest : 2|2@1+ (1,0) [0|3] "" Vector__XXX
 SG_ PARK_systemDtcPresent : 4|2@1+ (1,0) [0|3] "" Vector__XXX
 SG_ PARK_statusCounter : 12|4@1+ (1,0) [0|15] "" Vector__XXX
 SG_ PARK_statusChecksum : 16|8@1+ (1,0) [0|255] "" Vector__XXX
 SG_ PARK_majorVersion : 24|8@1+ (1,0) [0|255] "" Vector__XXX
 SG_ PARK_minorVersion : 32|8@1+ (1,0) [0|255] "" Vector__XXX
 SG_ PARK_subMinorVersion : 40|8@1+ (1,0) [0|255] "" Vector__XXX

BO_ 782 PARK_status2: 8 PARK
 SG_ PARK_frontSVACharID : 0|6@1+ (1,0) [0|63] "" Vector__XXX
 SG_ PARK_pscRightCurbType : 6|2@1+ (1,0) [0|3] "" Vector__XXX
 SG_ PARK_rearSVACharID : 8|6@1+ (1,0) [0|63] "" Vector__XXX
 SG_ PARK_pscLeftCurbType : 14|2@1+ (1,0) [0|3] "" Vector__XXX
 SG_ PARK_autoCalComplete : 16|1@1+ (1,0) [0|1] "" Vector__XXX
 SG_ PARK_geometryType : 17|2@1+ (1,0) [0|3] "" Vector__XXX
 SG_ PARK_tireFitment : 19|2@1+ (1,0) [0|3] "" Vector__XXX
 SG_ PARK_rackDetected : 21|2@1+ (1,0) [0|3] "" Vector__XXX
 SG_ PARK_sdiActive : 24|1@1+ (1,0) [0|1] "" Vector__XXX
 SG_ PARK_sdiNoise : 25|2@1+ (1,0) [0|3] "" Vector__XXX
 SG_ PARK_sdiBlindSpotRight : 27|2@1+ (1,0) [0|3] "" Vector__XXX
 SG_ PARK_sdiBlindSpotLeft : 29|2@1+ (1,0) [0|3] "" Vector__XXX
 SG_ PARK_sensorType : 32|2@1+ (1,0) [0|3] "" Vector__XXX
 SG_ PARK_status2Counter : 52|4@1+ (1,0) [0|15] "" Vector__XXX
 SG_ PARK_status2Checksum : 56|8@1+ (1,0) [0|255] "" Vector__XXX

BO_ 894 PARK_warningMatrix: 8 PARK
 SG_ PARK_matrixIndex M : 0|4@1+ (1,0) [0|15] "" Vector__XXX
 SG_ PARK_a001_s1_overTemp m0 : 4|1@1+ (1,0) [0|1] "" Vector__XXX
 SG_ PARK_a002_s1_internalFail m0 : 5|1@1+ (1,0) [0|1] "" Vector__XXX
 SG_ PARK_a003_s1_linCommError m0 : 6|1@1+ (1,0) [0|1] "" Vector__XXX
 SG_ PARK_a004_s1_blocked m0 : 7|1@1+ (1,0) [0|1] "" Vector__XXX
 SG_ PARK_a005_s1_crossTalk m0 : 8|1@1+ (1,0) [0|1] "" Vector__XXX
 SG_ PARK_a006_s2_overTemp m0 : 9|1@1+ (1,0) [0|1] "" Vector__XXX
 SG_ PARK_a007_s2_internalFail m0 : 10|1@1+ (1,0) [0|1] "" Vector__XXX
 SG_ PARK_a008_s2_linCommError m0 : 11|1@1+ (1,0) [0|1] "" Vector__XXX
 SG_ PARK_a009_s2_blocked m0 : 12|1@1+ (1,0) [0|1] "" Vector__XXX
 SG_ PARK_a010_s2_crossTalk m0 : 13|1@1+ (1,0) [0|1] "" Vector__XXX
 SG_ PARK_a011_s3_overTemp m0 : 14|1@1+ (1,0) [0|1] "" Vector__XXX
 SG_ PARK_a012_s3_internalFail m0 : 15|1@1+ (1,0) [0|1] "" Vector__XXX
 SG_ PARK_a013_s3_linCommError m0 : 16|1@1+ (1,0) [0|1] "" Vector__XXX
 SG_ PARK_a014_s3_blocked m0 : 17|1@1+ (1,0) [0|1] "" Vector__XXX
 SG_ PARK_a015_s3_crossTalk m0 : 18|1@1+ (1,0) [0|1] "" Vector__XXX
 SG_ PARK_a016_s4_overTemp m0 : 19|1@1+ (1,0) [0|1] "" Vector__XXX
 SG_ PARK_a017_s4_internalFail m0 : 20|1@1+ (1,0) [0|1] "" Vector__XXX
 SG_ PARK_a018_s4_linCommError m0 : 21|1@1+ (1,0) [0|1] "" Vector__XXX
 SG_ PARK_a019_s4_blocked m0 : 22|1@1+ (1,0) [0|1] "" Vector__XXX
 SG_ PARK_a020_s4_crossTalk m0 : 23|1@1+ (1,0) [0|1] "" Vector__XXX
 SG_ PARK_a021_s5_overTemp m0 : 24|1@1+ (1,0) [0|1] "" Vector__XXX
 SG_ PARK_a022_s5_internalFail m0 : 25|1@1+ (1,0) [0|1] "" Vector__XXX
 SG_ PARK_a023_s5_linCommError m0 : 26|1@1+ (1,0) [0|1] "" Vector__XXX
 SG_ PARK_a024_s5_blocked m0 : 27|1@1+ (1,0) [0|1] "" Vector__XXX
 SG_ PARK_a025_s5_crossTalk m0 : 28|1@1+ (1,0) [0|1] "" Vector__XXX
 SG_ PARK_a026_s6_overTemp m0 : 29|1@1+ (1,0) [0|1] "" Vector__XXX
 SG_ PARK_a027_s6_internalFail m0 : 30|1@1+ (1,0) [0|1] "" Vector__XXX
 SG_ PARK_a028_s6_linCommError m0 : 31|1@1+ (1,0) [0|1] "" Vector__XXX
 SG_ PARK_a029_s6_blocked m0 : 32|1@1+ (1,0) [0|1] "" Vector__XXX
 SG_ PARK_a030_s6_crossTalk m0 : 33|1@1+ (1,0) [0|1] "" Vector__XXX
 SG_ PARK_a031_s7_overTemp m0 : 34|1@1+ (1,0) [0|1] "" Vector__XXX
 SG_ PARK_a032_s7_internalFail m0 : 35|1@1+ (1,0) [0|1] "" Vector__XXX
 SG_ PARK_a033_s7_linCommError m0 : 36|1@1+ (1,0) [0|1] "" Vector__XXX
 SG_ PARK_a034_s7_blocked m0 : 37|1@1+ (1,0) [0|1] "" Vector__XXX
 SG_ PARK_a035_s7_crossTalk m0 : 38|1@1+ (1,0) [0|1] "" Vector__XXX
 SG_ PARK_a036_s8_overTemp m0 : 39|1@1+ (1,0) [0|1] "" Vector__XXX
 SG_ PARK_a037_s8_internalFail m0 : 40|1@1+ (1,0) [0|1] "" Vector__XXX
 SG_ PARK_a038_s8_linCommError m0 : 41|1@1+ (1,0) [0|1] "" Vector__XXX
 SG_ PARK_a039_s8_blocked m0 : 42|1@1+ (1,0) [0|1] "" Vector__XXX
 SG_ PARK_a040_s8_crossTalk m0 : 43|1@1+ (1,0) [0|1] "" Vector__XXX
 SG_ PARK_a041_s9_overTemp m0 : 44|1@1+ (1,0) [0|1] "" Vector__XXX
 SG_ PARK_a042_s9_internalFail m0 : 45|1@1+ (1,0) [0|1] "" Vector__XXX
 SG_ PARK_a043_s9_linCommError m0 : 46|1@1+ (1,0) [0|1] "" Vector__XXX
 SG_ PARK_a044_s9_blocked m0 : 47|1@1+ (1,0) [0|1] "" Vector__XXX
 SG_ PARK_a045_s9_crossTalk m0 : 48|1@1+ (1,0) [0|1] "" Vector__XXX
 SG_ PARK_a046_s10_overTemp m0 : 49|1@1+ (1,0) [0|1] "" Vector__XXX
 SG_ PARK_a047_s10_internalFail m0 : 50|1@1+ (1,0) [0|1] "" Vector__XXX
 SG_ PARK_a048_s10_linCommError m0 : 51|1@1+ (1,0) [0|1] "" Vector__XXX
 SG_ PARK_a049_s10_blocked m0 : 52|1@1+ (1,0) [0|1] "" Vector__XXX
 SG_ PARK_a050_s10_crossTalk m0 : 53|1@1+ (1,0) [0|1] "" Vector__XXX
 SG_ PARK_a051_s11_overTemp m0 : 54|1@1+ (1,0) [0|1] "" Vector__XXX
 SG_ PARK_a052_s11_internalFail m0 : 55|1@1+ (1,0) [0|1] "" Vector__XXX
 SG_ PARK_a053_s11_linCommError m0 : 56|1@1+ (1,0) [0|1] "" Vector__XXX
 SG_ PARK_a054_s11_blocked m0 : 57|1@1+ (1,0) [0|1] "" Vector__XXX
 SG_ PARK_a055_s11_crossTalk m0 : 58|1@1+ (1,0) [0|1] "" Vector__XXX
 SG_ PARK_a056_s12_overTemp m0 : 59|1@1+ (1,0) [0|1] "" Vector__XXX
 SG_ PARK_a057_s12_internalFail m0 : 60|1@1+ (1,0) [0|1] "" Vector__XXX
 SG_ PARK_a058_s12_linCommError m0 : 61|1@1+ (1,0) [0|1] "" Vector__XXX
 SG_ PARK_a059_s12_blocked m0 : 62|1@1+ (1,0) [0|1] "" Vector__XXX
 SG_ PARK_a060_s12_crossTalk m0 : 63|1@1+ (1,0) [0|1] "" Vector__XXX
 SG_ PARK_a061_ecuUnderVoltage m1 : 4|1@1+ (1,0) [0|1] "" Vector__XXX
 SG_ PARK_a062_ecuOverVoltage m1 : 5|1@1+ (1,0) [0|1] "" Vector__XXX
 SG_ PARK_a063_sensorVoltage m1 : 6|1@1+ (1,0) [0|1] "" Vector__XXX
 SG_ PARK_a064_ecuFault m1 : 7|1@1+ (1,0) [0|1] "" Vector__XXX
 SG_ PARK_a065_crcFault m1 : 8|1@1+ (1,0) [0|1] "" Vector__XXX
 SG_ PARK_a066_calibrationMissing m1 : 9|1@1+ (1,0) [0|1] "" Vector__XXX
 SG_ PARK_a067_privateCANBusOff m1 : 10|1@1+ (1,0) [0|1] "" Vector__XXX
 SG_ PARK_a068_hardwareWatchDog m1 : 11|1@1+ (1,0) [0|1] "" Vector__XXX
 SG_ PARK_a069_dasMia m1 : 12|1@1+ (1,0) [0|1] "" Vector__XXX
 SG_ PARK_a070_sccmMia m1 : 13|1@1+ (1,0) [0|1] "" Vector__XXX
 SG_ PARK_a071_diMia m1 : 14|1@1+ (1,0) [0|1] "" Vector__XXX
 SG_ PARK_a072_epasMia m1 : 15|1@1+ (1,0) [0|1] "" Vector__XXX
 SG_ PARK_a073_epbMia m1 : 16|1@1+ (1,0) [0|1] "" Vector__XXX
 SG_ PARK_a074_espMia m1 : 17|1@1+ (1,0) [0|1] "" Vector__XXX
 SG_ PARK_a075_rcmMia m1 : 18|1@1+ (1,0) [0|1] "" Vector__XXX
 SG_ PARK_a076_vcFrontMia m1 : 19|1@1+ (1,0) [0|1] "" Vector__XXX
 SG_ PARK_a077_dasError m1 : 20|1@1+ (1,0) [0|1] "" Vector__XXX
 SG_ PARK_a078_diError m1 : 21|1@1+ (1,0) [0|1] "" Vector__XXX
 SG_ PARK_a079_epasError m1 : 22|1@1+ (1,0) [0|1] "" Vector__XXX
 SG_ PARK_a080_epbError m1 : 23|1@1+ (1,0) [0|1] "" Vector__XXX
 SG_ PARK_a081_espError m1 : 24|1@1+ (1,0) [0|1] "" Vector__XXX
 SG_ PARK_a082_rcmError m1 : 25|1@1+ (1,0) [0|1] "" Vector__XXX
 SG_ PARK_a083_vcFrontError m1 : 26|1@1+ (1,0) [0|1] "" Vector__XXX
 SG_ PARK_a084_sccmError m1 : 27|1@1+ (1,0) [0|1] "" Vector__XXX
 SG_ PARK_a085_watchdogReset m1 : 28|1@1+ (1,0) [0|1] "" Vector__XXX
 SG_ PARK_a086_nvmFault m1 : 29|1@1+ (1,0) [0|1] "" Vector__XXX
 SG_ PARK_a087_sensorMismatchError m1 : 30|1@1+ (1,0) [0|1] "" Vector__XXX

CM_ BO_ 1486 "Parking assist sensors message: alert log";
CM_ SG_ 1486 PARK_alertID "Parking assist sensors: alert ID";
CM_ SG_ 1486 PARK_alertState "Parking assist sensors: alert state";
CM_ SG_ 1486 PARK_sw001_sensorTemperature "Parking assist sensors: sw001 sensor temperature";
CM_ SG_ 1486 PARK_sw002_membraneDisconct "Parking assist sensors: sw002 membrane disconct";
CM_ SG_ 1486 PARK_sw002_dampResistorFail "Parking assist sensors: sw002 damp resistor fail";
CM_ SG_ 1486 PARK_sw002_resonanceDrift "Parking assist sensors: sw002 resonance drift";
CM_ SG_ 1486 PARK_sw002_sensorCRC "Parking assist sensors: sw002 sensor CRC";
CM_ SG_ 1486 PARK_sw002_recieveFailure "Parking assist sensors: sw002 recieve failure";
CM_ SG_ 1486 PARK_sw002_diagnosticTransferErr "Parking assist sensors: sw002 diagnostic transfer error";
CM_ SG_ 1486 PARK_sw003_linError "Parking assist sensors: sw003 lin error";
CM_ SG_ 1486 PARK_sw003_linBusError "Parking assist sensors: sw003 lin bus error";
CM_ SG_ 1486 PARK_sw003_linFrameCountError "Parking assist sensors: sw003 lin frame count error";
CM_ SG_ 1486 PARK_sw004_reverbPeriod "Parking assist sensors: sw004 reverb period";
CM_ SG_ 1486 PARK_sw004_reverbTime "Parking assist sensors: sw004 reverb time";
CM_ SG_ 1486 PARK_sw004_highAttenTime "Parking assist sensors: sw004 high atten time";
CM_ SG_ 1486 PARK_sw004_closeConstEcho "Parking assist sensors: sw004 close const echo";
CM_ SG_ 1486 PARK_sw004_lowAttenTime "Parking assist sensors: sw004 low atten time";
CM_ SG_ 1486 PARK_sw004_attenTimeJitter "Parking assist sensors: sw004 atten time jitter";
CM_ SG_ 1486 PARK_sw004_reverbFreqJitter "Parking assist sensors: sw004 reverb freq jitter";
CM_ SG_ 1486 PARK_sw006_sensorTemperature "Parking assist sensors: sw006 sensor temperature";
CM_ SG_ 1486 PARK_sw007_membraneDisconct "Parking assist sensors: sw007 membrane disconct";
CM_ SG_ 1486 PARK_sw007_dampResistorFail "Parking assist sensors: sw007 damp resistor fail";
CM_ SG_ 1486 PARK_sw007_resonanceDrift "Parking assist sensors: sw007 resonance drift";
CM_ SG_ 1486 PARK_sw007_sensorCRC "Parking assist sensors: sw007 sensor CRC";
CM_ SG_ 1486 PARK_sw007_recieveFailure "Parking assist sensors: sw007 recieve failure";
CM_ SG_ 1486 PARK_sw007_diagnosticTransferErr "Parking assist sensors: sw007 diagnostic transfer error";
CM_ SG_ 1486 PARK_sw008_linError "Parking assist sensors: sw008 lin error";
CM_ SG_ 1486 PARK_sw008_linBusError "Parking assist sensors: sw008 lin bus error";
CM_ SG_ 1486 PARK_sw008_linFrameCountError "Parking assist sensors: sw008 lin frame count error";
CM_ SG_ 1486 PARK_sw009_reverbPeriod "Parking assist sensors: sw009 reverb period";
CM_ SG_ 1486 PARK_sw009_reverbTime "Parking assist sensors: sw009 reverb time";
CM_ SG_ 1486 PARK_sw009_highAttenTime "Parking assist sensors: sw009 high atten time";
CM_ SG_ 1486 PARK_sw009_closeConstEcho "Parking assist sensors: sw009 close const echo";
CM_ SG_ 1486 PARK_sw009_lowAttenTime "Parking assist sensors: sw009 low atten time";
CM_ SG_ 1486 PARK_sw009_attenTimeJitter "Parking assist sensors: sw009 atten time jitter";
CM_ SG_ 1486 PARK_sw009_reverbFreqJitter "Parking assist sensors: sw009 reverb freq jitter";
CM_ SG_ 1486 PARK_sw011_sensorTemperature "Parking assist sensors: sw011 sensor temperature";
CM_ SG_ 1486 PARK_sw012_membraneDisconct "Parking assist sensors: sw012 membrane disconct";
CM_ SG_ 1486 PARK_sw012_dampResistorFail "Parking assist sensors: sw012 damp resistor fail";
CM_ SG_ 1486 PARK_sw012_resonanceDrift "Parking assist sensors: sw012 resonance drift";
CM_ SG_ 1486 PARK_sw012_sensorCRC "Parking assist sensors: sw012 sensor CRC";
CM_ SG_ 1486 PARK_sw012_recieveFailure "Parking assist sensors: sw012 recieve failure";
CM_ SG_ 1486 PARK_sw012_diagnosticTransferErr "Parking assist sensors: sw012 diagnostic transfer error";
CM_ SG_ 1486 PARK_sw013_linError "Parking assist sensors: sw013 lin error";
CM_ SG_ 1486 PARK_sw013_linBusError "Parking assist sensors: sw013 lin bus error";
CM_ SG_ 1486 PARK_sw013_linFrameCountError "Parking assist sensors: sw013 lin frame count error";
CM_ SG_ 1486 PARK_sw014_reverbPeriod "Parking assist sensors: sw014 reverb period";
CM_ SG_ 1486 PARK_sw014_reverbTime "Parking assist sensors: sw014 reverb time";
CM_ SG_ 1486 PARK_sw014_highAttenTime "Parking assist sensors: sw014 high atten time";
CM_ SG_ 1486 PARK_sw014_closeConstEcho "Parking assist sensors: sw014 close const echo";
CM_ SG_ 1486 PARK_sw014_lowAttenTime "Parking assist sensors: sw014 low atten time";
CM_ SG_ 1486 PARK_sw014_attenTimeJitter "Parking assist sensors: sw014 atten time jitter";
CM_ SG_ 1486 PARK_sw014_reverbFreqJitter "Parking assist sensors: sw014 reverb freq jitter";
CM_ SG_ 1486 PARK_sw016_sensorTemperature "Parking assist sensors: sw016 sensor temperature";
CM_ SG_ 1486 PARK_sw017_membraneDisconct "Parking assist sensors: sw017 membrane disconct";
CM_ SG_ 1486 PARK_sw017_dampResistorFail "Parking assist sensors: sw017 damp resistor fail";
CM_ SG_ 1486 PARK_sw017_resonanceDrift "Parking assist sensors: sw017 resonance drift";
CM_ SG_ 1486 PARK_sw017_sensorCRC "Parking assist sensors: sw017 sensor CRC";
CM_ SG_ 1486 PARK_sw017_recieveFailure "Parking assist sensors: sw017 recieve failure";
CM_ SG_ 1486 PARK_sw017_diagnosticTransferErr "Parking assist sensors: sw017 diagnostic transfer error";
CM_ SG_ 1486 PARK_sw018_linError "Parking assist sensors: sw018 lin error";
CM_ SG_ 1486 PARK_sw018_linBusError "Parking assist sensors: sw018 lin bus error";
CM_ SG_ 1486 PARK_sw018_linFrameCountError "Parking assist sensors: sw018 lin frame count error";
CM_ SG_ 1486 PARK_sw019_reverbPeriod "Parking assist sensors: sw019 reverb period";
CM_ SG_ 1486 PARK_sw019_reverbTime "Parking assist sensors: sw019 reverb time";
CM_ SG_ 1486 PARK_sw019_highAttenTime "Parking assist sensors: sw019 high atten time";
CM_ SG_ 1486 PARK_sw019_closeConstEcho "Parking assist sensors: sw019 close const echo";
CM_ SG_ 1486 PARK_sw019_lowAttenTime "Parking assist sensors: sw019 low atten time";
CM_ SG_ 1486 PARK_sw019_attenTimeJitter "Parking assist sensors: sw019 atten time jitter";
CM_ SG_ 1486 PARK_sw019_reverbFreqJitter "Parking assist sensors: sw019 reverb freq jitter";
CM_ SG_ 1486 PARK_sw021_sensorTemperature "Parking assist sensors: sw021 sensor temperature";
CM_ SG_ 1486 PARK_sw022_membraneDisconct "Parking assist sensors: sw022 membrane disconct";
CM_ SG_ 1486 PARK_sw022_dampResistorFail "Parking assist sensors: sw022 damp resistor fail";
CM_ SG_ 1486 PARK_sw022_resonanceDrift "Parking assist sensors: sw022 resonance drift";
CM_ SG_ 1486 PARK_sw022_sensorCRC "Parking assist sensors: sw022 sensor CRC";
CM_ SG_ 1486 PARK_sw022_recieveFailure "Parking assist sensors: sw022 recieve failure";
CM_ SG_ 1486 PARK_sw022_diagnosticTransferErr "Parking assist sensors: sw022 diagnostic transfer error";
CM_ SG_ 1486 PARK_sw023_linError "Parking assist sensors: sw023 lin error";
CM_ SG_ 1486 PARK_sw023_linBusError "Parking assist sensors: sw023 lin bus error";
CM_ SG_ 1486 PARK_sw023_linFrameCountError "Parking assist sensors: sw023 lin frame count error";
CM_ SG_ 1486 PARK_sw024_reverbPeriod "Parking assist sensors: sw024 reverb period";
CM_ SG_ 1486 PARK_sw024_reverbTime "Parking assist sensors: sw024 reverb time";
CM_ SG_ 1486 PARK_sw024_highAttenTime "Parking assist sensors: sw024 high atten time";
CM_ SG_ 1486 PARK_sw024_closeConstEcho "Parking assist sensors: sw024 close const echo";
CM_ SG_ 1486 PARK_sw024_lowAttenTime "Parking assist sensors: sw024 low atten time";
CM_ SG_ 1486 PARK_sw024_attenTimeJitter "Parking assist sensors: sw024 atten time jitter";
CM_ SG_ 1486 PARK_sw024_reverbFreqJitter "Parking assist sensors: sw024 reverb freq jitter";
CM_ SG_ 1486 PARK_sw026_sensorTemperature "Parking assist sensors: sw026 sensor temperature";
CM_ SG_ 1486 PARK_sw027_membraneDisconct "Parking assist sensors: sw027 membrane disconct";
CM_ SG_ 1486 PARK_sw027_dampResistorFail "Parking assist sensors: sw027 damp resistor fail";
CM_ SG_ 1486 PARK_sw027_resonanceDrift "Parking assist sensors: sw027 resonance drift";
CM_ SG_ 1486 PARK_sw027_sensorCRC "Parking assist sensors: sw027 sensor CRC";
CM_ SG_ 1486 PARK_sw027_recieveFailure "Parking assist sensors: sw027 recieve failure";
CM_ SG_ 1486 PARK_sw027_diagnosticTransferErr "Parking assist sensors: sw027 diagnostic transfer error";
CM_ SG_ 1486 PARK_sw028_linError "Parking assist sensors: sw028 lin error";
CM_ SG_ 1486 PARK_sw028_linBusError "Parking assist sensors: sw028 lin bus error";
CM_ SG_ 1486 PARK_sw028_linFrameCountError "Parking assist sensors: sw028 lin frame count error";
CM_ SG_ 1486 PARK_sw029_reverbPeriod "Parking assist sensors: sw029 reverb period";
CM_ SG_ 1486 PARK_sw029_reverbTime "Parking assist sensors: sw029 reverb time";
CM_ SG_ 1486 PARK_sw029_highAttenTime "Parking assist sensors: sw029 high atten time";
CM_ SG_ 1486 PARK_sw029_closeConstEcho "Parking assist sensors: sw029 close const echo";
CM_ SG_ 1486 PARK_sw029_lowAttenTime "Parking assist sensors: sw029 low atten time";
CM_ SG_ 1486 PARK_sw029_attenTimeJitter "Parking assist sensors: sw029 atten time jitter";
CM_ SG_ 1486 PARK_sw029_reverbFreqJitter "Parking assist sensors: sw029 reverb freq jitter";
CM_ SG_ 1486 PARK_sw031_sensorTemperature "Parking assist sensors: sw031 sensor temperature";
CM_ SG_ 1486 PARK_sw032_membraneDisconct "Parking assist sensors: sw032 membrane disconct";
CM_ SG_ 1486 PARK_sw032_dampResistorFail "Parking assist sensors: sw032 damp resistor fail";
CM_ SG_ 1486 PARK_sw032_resonanceDrift "Parking assist sensors: sw032 resonance drift";
CM_ SG_ 1486 PARK_sw032_sensorCRC "Parking assist sensors: sw032 sensor CRC";
CM_ SG_ 1486 PARK_sw032_recieveFailure "Parking assist sensors: sw032 recieve failure";
CM_ SG_ 1486 PARK_sw032_diagnosticTransferErr "Parking assist sensors: sw032 diagnostic transfer error";
CM_ SG_ 1486 PARK_sw033_linError "Parking assist sensors: sw033 lin error";
CM_ SG_ 1486 PARK_sw033_linBusError "Parking assist sensors: sw033 lin bus error";
CM_ SG_ 1486 PARK_sw033_linFrameCountError "Parking assist sensors: sw033 lin frame count error";
CM_ SG_ 1486 PARK_sw034_reverbPeriod "Parking assist sensors: sw034 reverb period";
CM_ SG_ 1486 PARK_sw034_reverbTime "Parking assist sensors: sw034 reverb time";
CM_ SG_ 1486 PARK_sw034_highAttenTime "Parking assist sensors: sw034 high atten time";
CM_ SG_ 1486 PARK_sw034_closeConstEcho "Parking assist sensors: sw034 close const echo";
CM_ SG_ 1486 PARK_sw034_lowAttenTime "Parking assist sensors: sw034 low atten time";
CM_ SG_ 1486 PARK_sw034_attenTimeJitter "Parking assist sensors: sw034 atten time jitter";
CM_ SG_ 1486 PARK_sw034_reverbFreqJitter "Parking assist sensors: sw034 reverb freq jitter";
CM_ SG_ 1486 PARK_sw036_sensorTemperature "Parking assist sensors: sw036 sensor temperature";
CM_ SG_ 1486 PARK_sw037_membraneDisconct "Parking assist sensors: sw037 membrane disconct";
CM_ SG_ 1486 PARK_sw037_dampResistorFail "Parking assist sensors: sw037 damp resistor fail";
CM_ SG_ 1486 PARK_sw037_resonanceDrift "Parking assist sensors: sw037 resonance drift";
CM_ SG_ 1486 PARK_sw037_sensorCRC "Parking assist sensors: sw037 sensor CRC";
CM_ SG_ 1486 PARK_sw037_recieveFailure "Parking assist sensors: sw037 recieve failure";
CM_ SG_ 1486 PARK_sw037_diagnosticTransferErr "Parking assist sensors: sw037 diagnostic transfer error";
CM_ SG_ 1486 PARK_sw038_linError "Parking assist sensors: sw038 lin error";
CM_ SG_ 1486 PARK_sw038_linBusError "Parking assist sensors: sw038 lin bus error";
CM_ SG_ 1486 PARK_sw038_linFrameCountError "Parking assist sensors: sw038 lin frame count error";
CM_ SG_ 1486 PARK_sw039_reverbPeriod "Parking assist sensors: sw039 reverb period";
CM_ SG_ 1486 PARK_sw039_reverbTime "Parking assist sensors: sw039 reverb time";
CM_ SG_ 1486 PARK_sw039_highAttenTime "Parking assist sensors: sw039 high atten time";
CM_ SG_ 1486 PARK_sw039_closeConstEcho "Parking assist sensors: sw039 close const echo";
CM_ SG_ 1486 PARK_sw039_lowAttenTime "Parking assist sensors: sw039 low atten time";
CM_ SG_ 1486 PARK_sw039_attenTimeJitter "Parking assist sensors: sw039 atten time jitter";
CM_ SG_ 1486 PARK_sw039_reverbFreqJitter "Parking assist sensors: sw039 reverb freq jitter";
CM_ SG_ 1486 PARK_sw041_sensorTemperature "Parking assist sensors: sw041 sensor temperature";
CM_ SG_ 1486 PARK_sw042_membraneDisconct "Parking assist sensors: sw042 membrane disconct";
CM_ SG_ 1486 PARK_sw042_dampResistorFail "Parking assist sensors: sw042 damp resistor fail";
CM_ SG_ 1486 PARK_sw042_resonanceDrift "Parking assist sensors: sw042 resonance drift";
CM_ SG_ 1486 PARK_sw042_sensorCRC "Parking assist sensors: sw042 sensor CRC";
CM_ SG_ 1486 PARK_sw042_recieveFailure "Parking assist sensors: sw042 recieve failure";
CM_ SG_ 1486 PARK_sw042_diagnosticTransferErr "Parking assist sensors: sw042 diagnostic transfer error";
CM_ SG_ 1486 PARK_sw043_linError "Parking assist sensors: sw043 lin error";
CM_ SG_ 1486 PARK_sw043_linBusError "Parking assist sensors: sw043 lin bus error";
CM_ SG_ 1486 PARK_sw043_linFrameCountError "Parking assist sensors: sw043 lin frame count error";
CM_ SG_ 1486 PARK_sw044_reverbPeriod "Parking assist sensors: sw044 reverb period";
CM_ SG_ 1486 PARK_sw044_reverbTime "Parking assist sensors: sw044 reverb time";
CM_ SG_ 1486 PARK_sw044_highAttenTime "Parking assist sensors: sw044 high atten time";
CM_ SG_ 1486 PARK_sw044_closeConstEcho "Parking assist sensors: sw044 close const echo";
CM_ SG_ 1486 PARK_sw044_lowAttenTime "Parking assist sensors: sw044 low atten time";
CM_ SG_ 1486 PARK_sw044_attenTimeJitter "Parking assist sensors: sw044 atten time jitter";
CM_ SG_ 1486 PARK_sw044_reverbFreqJitter "Parking assist sensors: sw044 reverb freq jitter";
CM_ SG_ 1486 PARK_sw046_sensorTemperature "Parking assist sensors: sw046 sensor temperature";
CM_ SG_ 1486 PARK_sw047_membraneDisconct "Parking assist sensors: sw047 membrane disconct";
CM_ SG_ 1486 PARK_sw047_dampResistorFail "Parking assist sensors: sw047 damp resistor fail";
CM_ SG_ 1486 PARK_sw047_resonanceDrift "Parking assist sensors: sw047 resonance drift";
CM_ SG_ 1486 PARK_sw047_sensorCRC "Parking assist sensors: sw047 sensor CRC";
CM_ SG_ 1486 PARK_sw047_recieveFailure "Parking assist sensors: sw047 recieve failure";
CM_ SG_ 1486 PARK_sw047_diagnosticTransferErr "Parking assist sensors: sw047 diagnostic transfer error";
CM_ SG_ 1486 PARK_sw048_linError "Parking assist sensors: sw048 lin error";
CM_ SG_ 1486 PARK_sw048_linBusError "Parking assist sensors: sw048 lin bus error";
CM_ SG_ 1486 PARK_sw048_linFrameCountError "Parking assist sensors: sw048 lin frame count error";
CM_ SG_ 1486 PARK_sw049_reverbPeriod "Parking assist sensors: sw049 reverb period";
CM_ SG_ 1486 PARK_sw049_reverbTime "Parking assist sensors: sw049 reverb time";
CM_ SG_ 1486 PARK_sw049_highAttenTime "Parking assist sensors: sw049 high atten time";
CM_ SG_ 1486 PARK_sw049_closeConstEcho "Parking assist sensors: sw049 close const echo";
CM_ SG_ 1486 PARK_sw049_lowAttenTime "Parking assist sensors: sw049 low atten time";
CM_ SG_ 1486 PARK_sw049_attenTimeJitter "Parking assist sensors: sw049 atten time jitter";
CM_ SG_ 1486 PARK_sw049_reverbFreqJitter "Parking assist sensors: sw049 reverb freq jitter";
CM_ SG_ 1486 PARK_sw051_sensorTemperature "Parking assist sensors: sw051 sensor temperature";
CM_ SG_ 1486 PARK_sw052_membraneDisconct "Parking assist sensors: sw052 membrane disconct";
CM_ SG_ 1486 PARK_sw052_dampResistorFail "Parking assist sensors: sw052 damp resistor fail";
CM_ SG_ 1486 PARK_sw052_resonanceDrift "Parking assist sensors: sw052 resonance drift";
CM_ SG_ 1486 PARK_sw052_sensorCRC "Parking assist sensors: sw052 sensor CRC";
CM_ SG_ 1486 PARK_sw052_recieveFailure "Parking assist sensors: sw052 recieve failure";
CM_ SG_ 1486 PARK_sw052_diagnosticTransferErr "Parking assist sensors: sw052 diagnostic transfer error";
CM_ SG_ 1486 PARK_sw053_linError "Parking assist sensors: sw053 lin error";
CM_ SG_ 1486 PARK_sw053_linBusError "Parking assist sensors: sw053 lin bus error";
CM_ SG_ 1486 PARK_sw053_linFrameCountError "Parking assist sensors: sw053 lin frame count error";
CM_ SG_ 1486 PARK_sw054_reverbPeriod "Parking assist sensors: sw054 reverb period";
CM_ SG_ 1486 PARK_sw054_reverbTime "Parking assist sensors: sw054 reverb time";
CM_ SG_ 1486 PARK_sw054_highAttenTime "Parking assist sensors: sw054 high atten time";
CM_ SG_ 1486 PARK_sw054_closeConstEcho "Parking assist sensors: sw054 close const echo";
CM_ SG_ 1486 PARK_sw054_lowAttenTime "Parking assist sensors: sw054 low atten time";
CM_ SG_ 1486 PARK_sw054_attenTimeJitter "Parking assist sensors: sw054 atten time jitter";
CM_ SG_ 1486 PARK_sw054_reverbFreqJitter "Parking assist sensors: sw054 reverb freq jitter";
CM_ SG_ 1486 PARK_sw056_sensorTemperature "Parking assist sensors: sw056 sensor temperature";
CM_ SG_ 1486 PARK_sw057_membraneDisconct "Parking assist sensors: sw057 membrane disconct";
CM_ SG_ 1486 PARK_sw057_dampResistorFail "Parking assist sensors: sw057 damp resistor fail";
CM_ SG_ 1486 PARK_sw057_resonanceDrift "Parking assist sensors: sw057 resonance drift";
CM_ SG_ 1486 PARK_sw057_sensorCRC "Parking assist sensors: sw057 sensor CRC";
CM_ SG_ 1486 PARK_sw057_recieveFailure "Parking assist sensors: sw057 recieve failure";
CM_ SG_ 1486 PARK_sw057_diagnosticTransferErr "Parking assist sensors: sw057 diagnostic transfer error";
CM_ SG_ 1486 PARK_sw058_linError "Parking assist sensors: sw058 lin error";
CM_ SG_ 1486 PARK_sw058_linBusError "Parking assist sensors: sw058 lin bus error";
CM_ SG_ 1486 PARK_sw058_linFrameCountError "Parking assist sensors: sw058 lin frame count error";
CM_ SG_ 1486 PARK_sw059_reverbPeriod "Parking assist sensors: sw059 reverb period";
CM_ SG_ 1486 PARK_sw059_reverbTime "Parking assist sensors: sw059 reverb time";
CM_ SG_ 1486 PARK_sw059_highAttenTime "Parking assist sensors: sw059 high atten time";
CM_ SG_ 1486 PARK_sw059_closeConstEcho "Parking assist sensors: sw059 close const echo";
CM_ SG_ 1486 PARK_sw059_lowAttenTime "Parking assist sensors: sw059 low atten time";
CM_ SG_ 1486 PARK_sw059_attenTimeJitter "Parking assist sensors: sw059 atten time jitter";
CM_ SG_ 1486 PARK_sw059_reverbFreqJitter "Parking assist sensors: sw059 reverb freq jitter";
CM_ SG_ 1486 PARK_sw061_voltage "Parking assist sensors: sw061 voltage";
CM_ SG_ 1486 PARK_sw063_voltage "Parking assist sensors: sw063 voltage";
CM_ SG_ 1486 PARK_sw064_faultCode "Parking assist sensors: sw064 fault code";
CM_ SG_ 1486 PARK_sw065_expectedCRC "Parking assist sensors: sw065 expected CRC";
CM_ SG_ 1486 PARK_sw065_calculatedCRC "Parking assist sensors: sw065 calculated CRC";
CM_ SG_ 1486 PARK_sw066_placeHolder "Parking assist sensors: sw066 place holder";
CM_ SG_ 1486 PARK_sw068_placeHolder "Parking assist sensors: sw068 place holder";
CM_ SG_ 1486 PARK_sw069_messageID "Parking assist sensors: sw069 message ID";
CM_ SG_ 1486 PARK_sw070_messageID "Parking assist sensors: sw070 message ID";
CM_ SG_ 1486 PARK_sw071_messageID "Parking assist sensors: sw071 message ID";
CM_ SG_ 1486 PARK_sw072_messageID "Parking assist sensors: sw072 message ID";
CM_ SG_ 1486 PARK_sw073_messageID "Parking assist sensors: sw073 message ID";
CM_ SG_ 1486 PARK_sw074_messageID "Parking assist sensors: sw074 message ID";
CM_ SG_ 1486 PARK_sw075_messageID "Parking assist sensors: sw075 message ID";
CM_ SG_ 1486 PARK_sw076_messageID "Parking assist sensors: sw076 message ID";
CM_ SG_ 1486 PARK_sw077_errorExp "Parking assist sensors: sw077 error exp";
CM_ SG_ 1486 PARK_sw077_errorRx "Parking assist sensors: sw077 error rx";
CM_ SG_ 1486 PARK_sw077_messageID "Parking assist sensors: sw077 message ID";
CM_ SG_ 1486 PARK_sw077_errorType "Parking assist sensors: sw077 error type";
CM_ SG_ 1486 PARK_sw078_errorExp "Parking assist sensors: sw078 error exp";
CM_ SG_ 1486 PARK_sw078_errorRx "Parking assist sensors: sw078 error rx";
CM_ SG_ 1486 PARK_sw078_messageID "Parking assist sensors: sw078 message ID";
CM_ SG_ 1486 PARK_sw078_errorType "Parking assist sensors: sw078 error type";
CM_ SG_ 1486 PARK_sw079_errorExp "Parking assist sensors: sw079 error exp";
CM_ SG_ 1486 PARK_sw079_errorRx "Parking assist sensors: sw079 error rx";
CM_ SG_ 1486 PARK_sw079_messageID "Parking assist sensors: sw079 message ID";
CM_ SG_ 1486 PARK_sw079_errorType "Parking assist sensors: sw079 error type";
CM_ SG_ 1486 PARK_sw080_errorExp "Parking assist sensors: sw080 error exp";
CM_ SG_ 1486 PARK_sw080_errorRx "Parking assist sensors: sw080 error rx";
CM_ SG_ 1486 PARK_sw080_messageID "Parking assist sensors: sw080 message ID";
CM_ SG_ 1486 PARK_sw080_errorType "Parking assist sensors: sw080 error type";
CM_ SG_ 1486 PARK_sw081_errorExp "Parking assist sensors: sw081 error exp";
CM_ SG_ 1486 PARK_sw081_errorRx "Parking assist sensors: sw081 error rx";
CM_ SG_ 1486 PARK_sw081_messageID "Parking assist sensors: sw081 message ID";
CM_ SG_ 1486 PARK_sw081_errorType "Parking assist sensors: sw081 error type";
CM_ SG_ 1486 PARK_sw082_errorExp "Parking assist sensors: sw082 error exp";
CM_ SG_ 1486 PARK_sw082_errorRx "Parking assist sensors: sw082 error rx";
CM_ SG_ 1486 PARK_sw082_messageID "Parking assist sensors: sw082 message ID";
CM_ SG_ 1486 PARK_sw082_errorType "Parking assist sensors: sw082 error type";
CM_ SG_ 1486 PARK_sw083_errorExp "Parking assist sensors: sw083 error exp";
CM_ SG_ 1486 PARK_sw083_errorRx "Parking assist sensors: sw083 error rx";
CM_ SG_ 1486 PARK_sw083_messageID "Parking assist sensors: sw083 message ID";
CM_ SG_ 1486 PARK_sw083_errorType "Parking assist sensors: sw083 error type";
CM_ SG_ 1486 PARK_sw084_errorExp "Parking assist sensors: sw084 error exp";
CM_ SG_ 1486 PARK_sw084_errorRx "Parking assist sensors: sw084 error rx";
CM_ SG_ 1486 PARK_sw084_messageID "Parking assist sensors: sw084 message ID";
CM_ SG_ 1486 PARK_sw084_errorType "Parking assist sensors: sw084 error type";
CM_ SG_ 1486 PARK_sw086_writeRetryCounter "Parking assist sensors: sw086 write retry counter";
CM_ SG_ 1486 PARK_sw086_readRetryCounter "Parking assist sensors: sw086 read retry counter";
CM_ SG_ 1486 PARK_sw086_currentErrorCode "Parking assist sensors: sw086 current error code";
CM_ SG_ 1486 PARK_sw087_s1_sensorType "Parking assist sensors: sw087 s1 sensor type";
CM_ SG_ 1486 PARK_sw087_s2_sensorType "Parking assist sensors: sw087 s2 sensor type";
CM_ SG_ 1486 PARK_sw087_s3_sensorType "Parking assist sensors: sw087 s3 sensor type";
CM_ SG_ 1486 PARK_sw087_s4_sensorType "Parking assist sensors: sw087 s4 sensor type";
CM_ SG_ 1486 PARK_sw087_s5_sensorType "Parking assist sensors: sw087 s5 sensor type";
CM_ SG_ 1486 PARK_sw087_s6_sensorType "Parking assist sensors: sw087 s6 sensor type";
CM_ SG_ 1486 PARK_sw087_s7_sensorType "Parking assist sensors: sw087 s7 sensor type";
CM_ SG_ 1486 PARK_sw087_s8_sensorType "Parking assist sensors: sw087 s8 sensor type";
CM_ SG_ 1486 PARK_sw087_s9_sensorType "Parking assist sensors: sw087 s9 sensor type";
CM_ SG_ 1486 PARK_sw087_s10_sensorType "Parking assist sensors: sw087 s10 sensor type";
CM_ SG_ 1486 PARK_sw087_s11_sensorType "Parking assist sensors: sw087 s11 sensor type";
CM_ SG_ 1486 PARK_sw087_s12_sensorType "Parking assist sensors: sw087 s12 sensor type";
CM_ BO_ 806 "Parking assist sensors message: info";
CM_ SG_ 806 PARK_infoIndex "Parking assist sensors: info index";
CM_ SG_ 806 PARK_infoBuildType "Parking assist sensors: info build type";
CM_ SG_ 806 PARK_infoComponentID "Parking assist sensors: info component ID";
CM_ SG_ 806 PARK_infoPcbaID "Parking assist sensors: info pcba ID";
CM_ SG_ 806 PARK_infoAssemblyID "Parking assist sensors: info assembly ID";
CM_ SG_ 806 PARK_infoUsageID "Parking assist sensors: info usage ID";
CM_ SG_ 806 PARK_infoApplicationCRC "Parking assist sensors: info application CRC";
CM_ SG_ 806 PARK_infoBootUdsProtoVersion "Parking assist sensors: info boot uds proto version";
CM_ SG_ 806 PARK_infoBootloaderCRC "Parking assist sensors: info bootloader CRC";
CM_ BO_ 846 "Parking assist sensors message: pas front middle";
CM_ SG_ 846 PARK_frontLeftMiddleRawDistData "Zone defined as -38 degrees -> +12 degrees, distance to object in units of centimeters.";
CM_ SG_ 846 PARK_frontMiddleRawDistData "Zone defined as -12 degrees to +12 degrees, distance to object in units of centimeters.";
CM_ SG_ 846 PARK_frontRightMiddleRawDistData "Zone defined +12 degrees to +38 degreees, distance to object in units of centimeters.";
CM_ SG_ 846 PARK_pasFrontMiddleCounter "Parking assist sensors: pas front middle counter";
CM_ SG_ 846 PARK_pasFrontMiddleChecksum "Parking assist sensors: pas front middle checksum";
CM_ BO_ 862 "Parking assist sensors message: pas rear middle";
CM_ SG_ 862 PARK_rearLeftMiddleRawDistData "Zone defined as -124 degrees to -166 degrees, distance to object in units of centimeters.";
CM_ SG_ 862 PARK_rearMiddleRawDistData "Zone defined as -166 degrees to +166 degrees, distance to object in units of centimeters.";
CM_ SG_ 862 PARK_rearRightMiddleRawDistData "Zone defined as +166 degrees to +124 degrees, distance to object in units of centimeters.";
CM_ SG_ 862 PARK_pasRearMiddleCounter "Parking assist sensors: pas rear middle counter";
CM_ SG_ 862 PARK_pasRearMiddleChecksum "Parking assist sensors: pas rear middle checksum";
CM_ BO_ 926 "Parking assist sensors message: pas sides";
CM_ SG_ 926 PARK_rightSideFrontRawDistData "Right side (from inside the car) towards the front of the car (split evenly between axles).";
CM_ SG_ 926 PARK_rightSideRearRawDistData "Right side (from inside the car) towards the rear of the car (split evenly between axles).";
CM_ SG_ 926 PARK_leftSideFrontRawDistData "Left side (from inside the car) towards the front of the car (split evenly between axles).";
CM_ SG_ 926 PARK_leftSideRearRawDistData "Left side (from inside the car) towards the rear of the car (split evenly between axles).";
CM_ SG_ 926 PARK_pasSidesCounter "Parking assist sensors: pas sides counter";
CM_ SG_ 926 PARK_pasSidesChecksum "Parking assist sensors: pas sides checksum";
CM_ BO_ 606 "Parking assist sensors message: psc env slot";
CM_ SG_ 606 PARK_pscEnvSlotType "Parking assist sensors: psc env slot type";
CM_ SG_ 606 PARK_pscLeftParallelObj1X "Parking assist sensors: psc left parallel obj1 x";
CM_ SG_ 606 PARK_pscLeftParallelObj1Y "Parking assist sensors: psc left parallel obj1 y";
CM_ SG_ 606 PARK_pscLeftParallelObj1Alpha "Parking assist sensors: psc left parallel obj1 alpha";
CM_ SG_ 606 PARK_pscLeftParallelObj2Y "Parking assist sensors: psc left parallel obj2 y";
CM_ SG_ 606 PARK_pscLeftParallelObj2X "Parking assist sensors: psc left parallel obj2 x";
CM_ SG_ 606 PARK_pscLeftParallelObj2Alpha "Parking assist sensors: psc left parallel obj2 alpha";
CM_ SG_ 606 PARK_pscLeftCrossObj1X "Parking assist sensors: psc left cross obj1 x";
CM_ SG_ 606 PARK_pscLeftCrossObj1Y "Parking assist sensors: psc left cross obj1 y";
CM_ SG_ 606 PARK_pscLeftCrossObj1Alpha "Parking assist sensors: psc left cross obj1 alpha";
CM_ SG_ 606 PARK_pscLeftCrossObj2Y "Parking assist sensors: psc left cross obj2 y";
CM_ SG_ 606 PARK_pscLeftCrossObj2X "Parking assist sensors: psc left cross obj2 x";
CM_ SG_ 606 PARK_pscLeftCrossObj2Alpha "Parking assist sensors: psc left cross obj2 alpha";
CM_ SG_ 606 PARK_pscRightParallelObj1X "Parking assist sensors: psc right parallel obj1 x";
CM_ SG_ 606 PARK_pscRightParallelObj1Y "Parking assist sensors: psc right parallel obj1 y";
CM_ SG_ 606 PARK_pscRightParallelObj1Alpha "Parking assist sensors: psc right parallel obj1 alpha";
CM_ SG_ 606 PARK_pscRightParallelObj2Y "Parking assist sensors: psc right parallel obj2 y";
CM_ SG_ 606 PARK_pscRightParallelObj2X "Parking assist sensors: psc right parallel obj2 x";
CM_ SG_ 606 PARK_pscRightParallelObj2Alpha "Parking assist sensors: psc right parallel obj2 alpha";
CM_ SG_ 606 PARK_pscRightCrossObj1X "Parking assist sensors: psc right cross obj1 x";
CM_ SG_ 606 PARK_pscRightCrossObj1Y "Parking assist sensors: psc right cross obj1 y";
CM_ SG_ 606 PARK_pscRightCrossObj1Alpha "Parking assist sensors: psc right cross obj1 alpha";
CM_ SG_ 606 PARK_pscRightCrossObj2Y "Parking assist sensors: psc right cross obj2 y";
CM_ SG_ 606 PARK_pscRightCrossObj2X "Parking assist sensors: psc right cross obj2 x";
CM_ SG_ 606 PARK_pscRightCrossObj2Alpha "Parking assist sensors: psc right cross obj2 alpha";
CM_ BO_ 542 "Parking assist sensors message: psc status";
CM_ SG_ 542 PARK_pscParkStatus "Parking assist sensors: psc park status";
CM_ SG_ 542 PARK_pscParkAbortReason "Parking assist sensors: psc park abort reason";
CM_ SG_ 542 PARK_pscParallelSpace "The existence and type of a parallel parking slot identified by the ultrasonics.";
CM_ SG_ 542 PARK_pscCrossSpace "The type and existence of perpendicular parking slot identified through the ultrasonics";
CM_ SG_ 542 PARK_pscParallelRightParkable "Whether or not there is a valid path into a parallel parking slot on the right.";
CM_ SG_ 542 PARK_pscParallelLeftParkable "Whether or not there is a valid path into a parallel parking slot on the left.";
CM_ SG_ 542 PARK_pscCrossRightParkable "Parking assist sensors: psc cross right parkable";
CM_ SG_ 542 PARK_pscMaxVelocity "Parking assist sensors: psc max velocity";
CM_ SG_ 542 PARK_pscCrossLeftParkable "Parking assist sensors: psc cross left parkable";
CM_ SG_ 542 PARK_pscParkInstruction "The control request from PARK ECU during autopark manuever.";
CM_ SG_ 542 PARK_pscManeuverDistance "Real time updated path length from center of vehicle reference frame to desired center of vehicle at end of current parking manuever.";
CM_ SG_ 542 PARK_pscAngleActive "Parking assist sensors: psc angle active";
CM_ SG_ 542 PARK_pscAngleRequest "Parking assist sensors: psc angle request";
CM_ SG_ 542 PARK_pscStatusCounter "Parking assist sensors: psc status counter";
CM_ SG_ 542 PARK_pscStatusChecksum "Parking assist sensors: psc status checksum";
CM_ BO_ 590 "Parking assist sensors message: psc veh slot";
CM_ SG_ 590 PARK_pscVehSlotType "Parking assist sensors: psc veh slot type";
CM_ SG_ 590 PARK_pscLeftParallelVehX "Parking assist sensors: psc left parallel veh x";
CM_ SG_ 590 PARK_pscLeftParallelVehY "Parking assist sensors: psc left parallel veh y";
CM_ SG_ 590 PARK_pscLeftParallelPsi "Parking assist sensors: psc left parallel psi";
CM_ SG_ 590 PARK_pscLeftParallelSizeX "Parking assist sensors: psc left parallel size x";
CM_ SG_ 590 PARK_pscLeftParallelSizeY "Parking assist sensors: psc left parallel size y";
CM_ SG_ 590 PARK_pscLeftCrossVehX "Parking assist sensors: psc left cross veh x";
CM_ SG_ 590 PARK_pscLeftCrossVehY "Parking assist sensors: psc left cross veh y";
CM_ SG_ 590 PARK_pscLeftCrossPsi "Parking assist sensors: psc left cross psi";
CM_ SG_ 590 PARK_pscLeftCrossSizeX "Parking assist sensors: psc left cross size x";
CM_ SG_ 590 PARK_pscLeftCrossSizeY "Parking assist sensors: psc left cross size y";
CM_ SG_ 590 PARK_pscRightParallelVehX "Parking assist sensors: psc right parallel veh x";
CM_ SG_ 590 PARK_pscRightParallelVehY "Parking assist sensors: psc right parallel veh y";
CM_ SG_ 590 PARK_pscRightParallelPsi "Parking assist sensors: psc right parallel psi";
CM_ SG_ 590 PARK_pscRightParallelSizeX "Parking assist sensors: psc right parallel size x";
CM_ SG_ 590 PARK_pscRightParallelSizeY "Parking assist sensors: psc right parallel size y";
CM_ SG_ 590 PARK_pscRightCrossVehX "Parking assist sensors: psc right cross veh x";
CM_ SG_ 590 PARK_pscRightCrossVehY "Parking assist sensors: psc right cross veh y";
CM_ SG_ 590 PARK_pscRightCrossPsi "Parking assist sensors: psc right cross psi";
CM_ SG_ 590 PARK_pscRightCrossSizeX "Parking assist sensors: psc right cross size x";
CM_ SG_ 590 PARK_pscRightCrossSizeY "Parking assist sensors: psc right cross size y";
CM_ BO_ 526 "Parking assist sensors message: sdi front";
CM_ SG_ 526 PARK_sdiSensor1RawDistData "Parking assist sensors: sdi sensor1 raw dist data";
CM_ SG_ 526 PARK_sdiSensor2RawDistData "Parking assist sensors: sdi sensor2 raw dist data";
CM_ SG_ 526 PARK_sdiSensor3RawDistData "Parking assist sensors: sdi sensor3 raw dist data";
CM_ SG_ 526 PARK_sdiSensor4RawDistData "Parking assist sensors: sdi sensor4 raw dist data";
CM_ SG_ 526 PARK_sdiSensor5RawDistData "Parking assist sensors: sdi sensor5 raw dist data";
CM_ SG_ 526 PARK_sdiSensor6RawDistData "Parking assist sensors: sdi sensor6 raw dist data";
CM_ SG_ 526 PARK_sdiFrontCounter "Parking assist sensors: sdi front counter";
CM_ SG_ 526 PARK_sdiFrontChecksum "Parking assist sensors: sdi front checksum";
CM_ BO_ 558 "Parking assist sensors message: sdi rear";
CM_ SG_ 558 PARK_sdiSensor7RawDistData "Parking assist sensors: sdi sensor7 raw dist data";
CM_ SG_ 558 PARK_sdiSensor8RawDistData "Parking assist sensors: sdi sensor8 raw dist data";
CM_ SG_ 558 PARK_sdiSensor9RawDistData "Parking assist sensors: sdi sensor9 raw dist data";
CM_ SG_ 558 PARK_sdiSensor10RawDistData "Parking assist sensors: sdi sensor10 raw dist data";
CM_ SG_ 558 PARK_sdiSensor11RawDistData "Parking assist sensors: sdi sensor11 raw dist data";
CM_ SG_ 558 PARK_sdiSensor12RawDistData "Parking assist sensors: sdi sensor12 raw dist data";
CM_ SG_ 558 PARK_sdiRearCounter "Parking assist sensors: sdi rear counter";
CM_ SG_ 558 PARK_sdiRearChecksum "Parking assist sensors: sdi rear checksum";
CM_ BO_ 814 "Parking assist sensors message: sensor status front";
CM_ SG_ 814 PARK_frontRightSensorState "Reports the state of the front right ultrasonic sensor.";
CM_ SG_ 814 PARK_frontRightMiddleSensorState "Reports the state of the front right middle ultrasonic sensor.";
CM_ SG_ 814 PARK_frontLeftMiddleSensorState "Reports the state of the front left middle ultrasonic sensor.";
CM_ SG_ 814 PARK_frontLeftSensorState "Reports the state of the front left ultrasonic sensor.";
CM_ SG_ 814 PARK_frontLeftRawDistData "Zone defined as -90 degrees -> -38 degrees, distance to object in units of centimeters.";
CM_ SG_ 814 PARK_frontRightRawDistData "Zone defined as +38 degrees -> +90 degrees, distance to object in units of centimeters.";
CM_ SG_ 814 PARK_systemStatusFront "Parking assist sensors: system status front";
CM_ SG_ 814 PARK_frontDtcPresent "Parking assist sensors: front dtc present";
CM_ SG_ 814 PARK_sensorStatusFrontCounter "Parking assist sensors: sensor status front counter";
CM_ SG_ 814 PARK_sensorStatusFrontChecksum "Parking assist sensors: sensor status front checksum";
CM_ BO_ 830 "Parking assist sensors message: sensor status rear";
CM_ SG_ 830 PARK_rearRightSensorState "Reports the state of the rear right ultrasonic sensor.";
CM_ SG_ 830 PARK_rearRightMiddleSensorState "Reports the state of the rear right middle ultrasonic sensor.";
CM_ SG_ 830 PARK_rearLeftMiddleSensorState "Reports the state of the rear left middle ultrasonic sensor.";
CM_ SG_ 830 PARK_rearLeftSensorState "Reports the state of the rear left ultrasonic sensor.";
CM_ SG_ 830 PARK_rearLeftRawDistData "Zone defined as -90 degrees to -125 degrees, distance to object in units of centimeters.";
CM_ SG_ 830 PARK_rearRightRawDistData "Zone defined as +125 degrees to +90 degrees, distance to object in units of centimeters.";
CM_ SG_ 830 PARK_systemStatusRear "Parking assist sensors: system status rear";
CM_ SG_ 830 PARK_rearDtcPresent "Parking assist sensors: rear dtc present";
CM_ SG_ 830 PARK_sensorStatusRearCounter "Parking assist sensors: sensor status rear counter";
CM_ SG_ 830 PARK_sensorStatusRearChecksum "Parking assist sensors: sensor status rear checksum";
CM_ BO_ 799 "Parking assist sensors message: status";
CM_ SG_ 799 PARK_status "Indicates status of park assist function";
CM_ SG_ 799 PARK_serviceRequest "Indicates whether or not PARK sensors/ECU require service";
CM_ SG_ 799 PARK_systemDtcPresent "Boolean indicating whether or not there is a DTC present";
CM_ SG_ 799 PARK_statusCounter "Parking assist sensors: status counter";
CM_ SG_ 799 PARK_statusChecksum "Parking assist sensors: status checksum";
CM_ SG_ 799 PARK_majorVersion "Parking assist sensors: major version";
CM_ SG_ 799 PARK_minorVersion "Parking assist sensors: minor version";
CM_ SG_ 799 PARK_subMinorVersion "Parking assist sensors: sub minor version";
CM_ BO_ 782 "Parking assist sensors message: status2";
CM_ SG_ 782 PARK_frontSVACharID "Parking assist sensors: front SVA char ID";
CM_ SG_ 782 PARK_pscRightCurbType "The type of curb for the parallel parking slot on the right side.";
CM_ SG_ 782 PARK_rearSVACharID "Parking assist sensors: rear SVA char ID";
CM_ SG_ 782 PARK_pscLeftCurbType "The type of curb identified for a parallel parking space on the left.";
CM_ SG_ 782 PARK_autoCalComplete "Parking assist sensors: auto cal complete";
CM_ SG_ 782 PARK_geometryType "Parking assist sensors: geometry type";
CM_ SG_ 782 PARK_tireFitment "Parking assist sensors: tire fitment";
CM_ SG_ 782 PARK_rackDetected "Parking assist sensors: rack detected";
CM_ SG_ 782 PARK_sdiActive "Whether or not the raw sensor measurements from the ultrasonics are present and valid";
CM_ SG_ 782 PARK_sdiNoise "The output of the noise detection algorithm for raw sensor measurements, indicates if the measurements are degraded due to ambient noise.";
CM_ SG_ 782 PARK_sdiBlindSpotRight "The output of the PARK ECU blindspot algorithm on the right side of the car, indicates the presence of a vehicle.";
CM_ SG_ 782 PARK_sdiBlindSpotLeft "The output of the PARK ECU blindspot algorithm on the left side of the car, indicates the presence of a vehicle.";
CM_ SG_ 782 PARK_sensorType "Parking assist sensors: sensor type";
CM_ SG_ 782 PARK_status2Counter "Parking assist sensors: status2 counter";
CM_ SG_ 782 PARK_status2Checksum "Parking assist sensors: status2 checksum";
CM_ BO_ 894 "Parking assist sensors message: warning matrix";
CM_ SG_ 894 PARK_matrixIndex "Parking assist sensors: matrix index";
CM_ SG_ 894 PARK_a001_s1_overTemp "Parking assist sensors: a001 s1 over temp";
CM_ SG_ 894 PARK_a002_s1_internalFail "Parking assist sensors: a002 s1 internal fail";
CM_ SG_ 894 PARK_a003_s1_linCommError "Parking assist sensors: a003 s1 lin comm error";
CM_ SG_ 894 PARK_a004_s1_blocked "Parking assist sensors: a004 s1 blocked";
CM_ SG_ 894 PARK_a005_s1_crossTalk "Parking assist sensors: a005 s1 cross talk";
CM_ SG_ 894 PARK_a006_s2_overTemp "Parking assist sensors: a006 s2 over temp";
CM_ SG_ 894 PARK_a007_s2_internalFail "Parking assist sensors: a007 s2 internal fail";
CM_ SG_ 894 PARK_a008_s2_linCommError "Parking assist sensors: a008 s2 lin comm error";
CM_ SG_ 894 PARK_a009_s2_blocked "Parking assist sensors: a009 s2 blocked";
CM_ SG_ 894 PARK_a010_s2_crossTalk "Parking assist sensors: a010 s2 cross talk";
CM_ SG_ 894 PARK_a011_s3_overTemp "Parking assist sensors: a011 s3 over temp";
CM_ SG_ 894 PARK_a012_s3_internalFail "Parking assist sensors: a012 s3 internal fail";
CM_ SG_ 894 PARK_a013_s3_linCommError "Parking assist sensors: a013 s3 lin comm error";
CM_ SG_ 894 PARK_a014_s3_blocked "Parking assist sensors: a014 s3 blocked";
CM_ SG_ 894 PARK_a015_s3_crossTalk "Parking assist sensors: a015 s3 cross talk";
CM_ SG_ 894 PARK_a016_s4_overTemp "Parking assist sensors: a016 s4 over temp";
CM_ SG_ 894 PARK_a017_s4_internalFail "Parking assist sensors: a017 s4 internal fail";
CM_ SG_ 894 PARK_a018_s4_linCommError "Parking assist sensors: a018 s4 lin comm error";
CM_ SG_ 894 PARK_a019_s4_blocked "Parking assist sensors: a019 s4 blocked";
CM_ SG_ 894 PARK_a020_s4_crossTalk "Parking assist sensors: a020 s4 cross talk";
CM_ SG_ 894 PARK_a021_s5_overTemp "Parking assist sensors: a021 s5 over temp";
CM_ SG_ 894 PARK_a022_s5_internalFail "Parking assist sensors: a022 s5 internal fail";
CM_ SG_ 894 PARK_a023_s5_linCommError "Parking assist sensors: a023 s5 lin comm error";
CM_ SG_ 894 PARK_a024_s5_blocked "Parking assist sensors: a024 s5 blocked";
CM_ SG_ 894 PARK_a025_s5_crossTalk "Parking assist sensors: a025 s5 cross talk";
CM_ SG_ 894 PARK_a026_s6_overTemp "Parking assist sensors: a026 s6 over temp";
CM_ SG_ 894 PARK_a027_s6_internalFail "Parking assist sensors: a027 s6 internal fail";
CM_ SG_ 894 PARK_a028_s6_linCommError "Parking assist sensors: a028 s6 lin comm error";
CM_ SG_ 894 PARK_a029_s6_blocked "Parking assist sensors: a029 s6 blocked";
CM_ SG_ 894 PARK_a030_s6_crossTalk "Parking assist sensors: a030 s6 cross talk";
CM_ SG_ 894 PARK_a031_s7_overTemp "Parking assist sensors: a031 s7 over temp";
CM_ SG_ 894 PARK_a032_s7_internalFail "Parking assist sensors: a032 s7 internal fail";
CM_ SG_ 894 PARK_a033_s7_linCommError "Parking assist sensors: a033 s7 lin comm error";
CM_ SG_ 894 PARK_a034_s7_blocked "Parking assist sensors: a034 s7 blocked";
CM_ SG_ 894 PARK_a035_s7_crossTalk "Parking assist sensors: a035 s7 cross talk";
CM_ SG_ 894 PARK_a036_s8_overTemp "Parking assist sensors: a036 s8 over temp";
CM_ SG_ 894 PARK_a037_s8_internalFail "Parking assist sensors: a037 s8 internal fail";
CM_ SG_ 894 PARK_a038_s8_linCommError "Parking assist sensors: a038 s8 lin comm error";
CM_ SG_ 894 PARK_a039_s8_blocked "Parking assist sensors: a039 s8 blocked";
CM_ SG_ 894 PARK_a040_s8_crossTalk "Parking assist sensors: a040 s8 cross talk";
CM_ SG_ 894 PARK_a041_s9_overTemp "Parking assist sensors: a041 s9 over temp";
CM_ SG_ 894 PARK_a042_s9_internalFail "Parking assist sensors: a042 s9 internal fail";
CM_ SG_ 894 PARK_a043_s9_linCommError "Parking assist sensors: a043 s9 lin comm error";
CM_ SG_ 894 PARK_a044_s9_blocked "Parking assist sensors: a044 s9 blocked";
CM_ SG_ 894 PARK_a045_s9_crossTalk "Parking assist sensors: a045 s9 cross talk";
CM_ SG_ 894 PARK_a046_s10_overTemp "Parking assist sensors: a046 s10 over temp";
CM_ SG_ 894 PARK_a047_s10_internalFail "Parking assist sensors: a047 s10 internal fail";
CM_ SG_ 894 PARK_a048_s10_linCommError "Parking assist sensors: a048 s10 lin comm error";
CM_ SG_ 894 PARK_a049_s10_blocked "Parking assist sensors: a049 s10 blocked";
CM_ SG_ 894 PARK_a050_s10_crossTalk "Parking assist sensors: a050 s10 cross talk";
CM_ SG_ 894 PARK_a051_s11_overTemp "Parking assist sensors: a051 s11 over temp";
CM_ SG_ 894 PARK_a052_s11_internalFail "Parking assist sensors: a052 s11 internal fail";
CM_ SG_ 894 PARK_a053_s11_linCommError "Parking assist sensors: a053 s11 lin comm error";
CM_ SG_ 894 PARK_a054_s11_blocked "Parking assist sensors: a054 s11 blocked";
CM_ SG_ 894 PARK_a055_s11_crossTalk "Parking assist sensors: a055 s11 cross talk";
CM_ SG_ 894 PARK_a056_s12_overTemp "Parking assist sensors: a056 s12 over temp";
CM_ SG_ 894 PARK_a057_s12_internalFail "Parking assist sensors: a057 s12 internal fail";
CM_ SG_ 894 PARK_a058_s12_linCommError "Parking assist sensors: a058 s12 lin comm error";
CM_ SG_ 894 PARK_a059_s12_blocked "Parking assist sensors: a059 s12 blocked";
CM_ SG_ 894 PARK_a060_s12_crossTalk "Parking assist sensors: a060 s12 cross talk";
CM_ SG_ 894 PARK_a061_ecuUnderVoltage "Parking assist sensors: a061 ecu under voltage";
CM_ SG_ 894 PARK_a062_ecuOverVoltage "Parking assist sensors: a062 ecu over voltage";
CM_ SG_ 894 PARK_a063_sensorVoltage "Parking assist sensors: a063 sensor voltage";
CM_ SG_ 894 PARK_a064_ecuFault "Parking assist sensors: a064 ecu fault";
CM_ SG_ 894 PARK_a065_crcFault "Parking assist sensors: a065 crc fault";
CM_ SG_ 894 PARK_a066_calibrationMissing "Parking assist sensors: a066 calibration missing";
CM_ SG_ 894 PARK_a067_privateCANBusOff "Parking assist sensors: a067 private CAN bus off";
CM_ SG_ 894 PARK_a068_hardwareWatchDog "Parking assist sensors: a068 hardware watch dog";
CM_ SG_ 894 PARK_a069_dasMia "Parking assist sensors: a069 das mia";
CM_ SG_ 894 PARK_a070_sccmMia "Parking assist sensors: a070 sccm mia";
CM_ SG_ 894 PARK_a071_diMia "Parking assist sensors: a071 di mia";
CM_ SG_ 894 PARK_a072_epasMia "Parking assist sensors: a072 epas mia";
CM_ SG_ 894 PARK_a073_epbMia "Parking assist sensors: a073 epb mia";
CM_ SG_ 894 PARK_a074_espMia "Parking assist sensors: a074 esp mia";
CM_ SG_ 894 PARK_a075_rcmMia "Parking assist sensors: a075 rcm mia";
CM_ SG_ 894 PARK_a076_vcFrontMia "Parking assist sensors: a076 vc front mia";
CM_ SG_ 894 PARK_a077_dasError "Parking assist sensors: a077 das error";
CM_ SG_ 894 PARK_a078_diError "Parking assist sensors: a078 di error";
CM_ SG_ 894 PARK_a079_epasError "Parking assist sensors: a079 epas error";
CM_ SG_ 894 PARK_a080_epbError "Parking assist sensors: a080 epb error";
CM_ SG_ 894 PARK_a081_espError "Parking assist sensors: a081 esp error";
CM_ SG_ 894 PARK_a082_rcmError "Parking assist sensors: a082 rcm error";
CM_ SG_ 894 PARK_a083_vcFrontError "Parking assist sensors: a083 vc front error";
CM_ SG_ 894 PARK_a084_sccmError "Parking assist sensors: a084 sccm error";
CM_ SG_ 894 PARK_a085_watchdogReset "Parking assist sensors: a085 watchdog reset";
CM_ SG_ 894 PARK_a086_nvmFault "Parking assist sensors: a086 nvm fault";
CM_ SG_ 894 PARK_a087_sensorMismatchError "Parking assist sensors: a087 sensor mismatch error";
BA_DEF_ BO_ "GenMsgCycleTime" INT 0 3600000;
BA_DEF_ BO_ "GenMsgSendType" ENUM "Cyclic","NotUsed","NotUsed","NotUsed","NotUsed","NotUsed","NotUsed","IfActive","NoMsgSendType","NotUsed";
BA_DEF_ BO_ "VFrameFormat" ENUM "StandardCAN","ExtendedCAN","reserved","J1939PG","reserved","reserved","reserved","reserved","reserved","reserved","reserved","reserved","reserved","reserved","StandardCAN_FD","ExtendedCAN_FD";
BA_DEF_ BO_ "CANFD_BRS" ENUM "0","1";
BA_DEF_ SG_ "SystemSignalLongSymbol" STRING;
BA_DEF_ SG_ "Confidence" ENUM "layout-only","plausible","validated";
BA_DEF_DEF_ "GenMsgCycleTime" 0;
BA_DEF_DEF_ "GenMsgSendType" "NoMsgSendType";
BA_DEF_DEF_ "VFrameFormat" "StandardCAN";
BA_DEF_DEF_ "CANFD_BRS" "1";
BA_DEF_DEF_ "SystemSignalLongSymbol" "";
BA_DEF_DEF_ "Confidence" "layout-only";
BA_ "SystemSignalLongSymbol" SG_ 1486 PARK_sw002_diagnosticTransferErr "PARK_sw002_diagnosticTransferError";
BA_ "SystemSignalLongSymbol" SG_ 1486 PARK_sw007_diagnosticTransferErr "PARK_sw007_diagnosticTransferError";
BA_ "SystemSignalLongSymbol" SG_ 1486 PARK_sw012_diagnosticTransferErr "PARK_sw012_diagnosticTransferError";
BA_ "SystemSignalLongSymbol" SG_ 1486 PARK_sw017_diagnosticTransferErr "PARK_sw017_diagnosticTransferError";
BA_ "SystemSignalLongSymbol" SG_ 1486 PARK_sw022_diagnosticTransferErr "PARK_sw022_diagnosticTransferError";
BA_ "SystemSignalLongSymbol" SG_ 1486 PARK_sw027_diagnosticTransferErr "PARK_sw027_diagnosticTransferError";
BA_ "SystemSignalLongSymbol" SG_ 1486 PARK_sw032_diagnosticTransferErr "PARK_sw032_diagnosticTransferError";
BA_ "SystemSignalLongSymbol" SG_ 1486 PARK_sw037_diagnosticTransferErr "PARK_sw037_diagnosticTransferError";
BA_ "SystemSignalLongSymbol" SG_ 1486 PARK_sw042_diagnosticTransferErr "PARK_sw042_diagnosticTransferError";
BA_ "SystemSignalLongSymbol" SG_ 1486 PARK_sw047_diagnosticTransferErr "PARK_sw047_diagnosticTransferError";
BA_ "SystemSignalLongSymbol" SG_ 1486 PARK_sw052_diagnosticTransferErr "PARK_sw052_diagnosticTransferError";
BA_ "SystemSignalLongSymbol" SG_ 1486 PARK_sw057_diagnosticTransferErr "PARK_sw057_diagnosticTransferError";
BA_ "Confidence" SG_ 806 PARK_infoBuildType 1;
BA_ "Confidence" SG_ 846 PARK_frontLeftMiddleRawDistData 1;
BA_ "Confidence" SG_ 846 PARK_frontMiddleRawDistData 1;
BA_ "Confidence" SG_ 846 PARK_frontRightMiddleRawDistData 1;
BA_ "Confidence" SG_ 862 PARK_rearLeftMiddleRawDistData 1;
BA_ "Confidence" SG_ 862 PARK_rearMiddleRawDistData 1;
BA_ "Confidence" SG_ 862 PARK_rearRightMiddleRawDistData 1;
BA_ "Confidence" SG_ 926 PARK_rightSideFrontRawDistData 1;
BA_ "Confidence" SG_ 926 PARK_rightSideRearRawDistData 1;
BA_ "Confidence" SG_ 926 PARK_leftSideFrontRawDistData 1;
BA_ "Confidence" SG_ 926 PARK_leftSideRearRawDistData 1;
BA_ "Confidence" SG_ 606 PARK_pscLeftParallelObj1X 1;
BA_ "Confidence" SG_ 606 PARK_pscLeftParallelObj1Y 1;
BA_ "Confidence" SG_ 606 PARK_pscLeftParallelObj1Alpha 1;
BA_ "Confidence" SG_ 606 PARK_pscLeftParallelObj2Y 1;
BA_ "Confidence" SG_ 606 PARK_pscLeftParallelObj2X 1;
BA_ "Confidence" SG_ 606 PARK_pscLeftParallelObj2Alpha 1;
BA_ "Confidence" SG_ 606 PARK_pscLeftCrossObj1X 1;
BA_ "Confidence" SG_ 606 PARK_pscLeftCrossObj1Y 1;
BA_ "Confidence" SG_ 606 PARK_pscLeftCrossObj1Alpha 1;
BA_ "Confidence" SG_ 606 PARK_pscLeftCrossObj2Y 1;
BA_ "Confidence" SG_ 606 PARK_pscLeftCrossObj2X 1;
BA_ "Confidence" SG_ 606 PARK_pscLeftCrossObj2Alpha 1;
BA_ "Confidence" SG_ 606 PARK_pscRightParallelObj1X 1;
BA_ "Confidence" SG_ 606 PARK_pscRightParallelObj1Y 1;
BA_ "Confidence" SG_ 606 PARK_pscRightParallelObj1Alpha 1;
BA_ "Confidence" SG_ 606 PARK_pscRightParallelObj2Y 1;
BA_ "Confidence" SG_ 606 PARK_pscRightParallelObj2X 1;
BA_ "Confidence" SG_ 606 PARK_pscRightParallelObj2Alpha 1;
BA_ "Confidence" SG_ 606 PARK_pscRightCrossObj1X 1;
BA_ "Confidence" SG_ 606 PARK_pscRightCrossObj1Y 1;
BA_ "Confidence" SG_ 606 PARK_pscRightCrossObj1Alpha 1;
BA_ "Confidence" SG_ 606 PARK_pscRightCrossObj2Y 1;
BA_ "Confidence" SG_ 606 PARK_pscRightCrossObj2X 1;
BA_ "Confidence" SG_ 606 PARK_pscRightCrossObj2Alpha 1;
BA_ "Confidence" SG_ 542 PARK_pscParkStatus 1;
BA_ "Confidence" SG_ 542 PARK_pscParkAbortReason 1;
BA_ "Confidence" SG_ 542 PARK_pscParallelSpace 1;
BA_ "Confidence" SG_ 542 PARK_pscCrossSpace 1;
BA_ "Confidence" SG_ 542 PARK_pscParallelRightParkable 1;
BA_ "Confidence" SG_ 542 PARK_pscParallelLeftParkable 1;
BA_ "Confidence" SG_ 542 PARK_pscCrossRightParkable 1;
BA_ "Confidence" SG_ 542 PARK_pscMaxVelocity 1;
BA_ "Confidence" SG_ 542 PARK_pscCrossLeftParkable 1;
BA_ "Confidence" SG_ 542 PARK_pscParkInstruction 1;
BA_ "Confidence" SG_ 542 PARK_pscManeuverDistance 1;
BA_ "Confidence" SG_ 542 PARK_pscAngleActive 1;
BA_ "Confidence" SG_ 542 PARK_pscAngleRequest 1;
BA_ "Confidence" SG_ 590 PARK_pscLeftParallelVehX 1;
BA_ "Confidence" SG_ 590 PARK_pscLeftParallelVehY 1;
BA_ "Confidence" SG_ 590 PARK_pscLeftParallelPsi 1;
BA_ "Confidence" SG_ 590 PARK_pscLeftParallelSizeX 1;
BA_ "Confidence" SG_ 590 PARK_pscLeftParallelSizeY 1;
BA_ "Confidence" SG_ 590 PARK_pscLeftCrossVehX 1;
BA_ "Confidence" SG_ 590 PARK_pscLeftCrossVehY 1;
BA_ "Confidence" SG_ 590 PARK_pscLeftCrossPsi 1;
BA_ "Confidence" SG_ 590 PARK_pscLeftCrossSizeX 1;
BA_ "Confidence" SG_ 590 PARK_pscLeftCrossSizeY 1;
BA_ "Confidence" SG_ 590 PARK_pscRightParallelVehX 1;
BA_ "Confidence" SG_ 590 PARK_pscRightParallelVehY 1;
BA_ "Confidence" SG_ 590 PARK_pscRightParallelPsi 1;
BA_ "Confidence" SG_ 590 PARK_pscRightParallelSizeX 1;
BA_ "Confidence" SG_ 590 PARK_pscRightParallelSizeY 1;
BA_ "Confidence" SG_ 590 PARK_pscRightCrossVehX 1;
BA_ "Confidence" SG_ 590 PARK_pscRightCrossVehY 1;
BA_ "Confidence" SG_ 590 PARK_pscRightCrossPsi 1;
BA_ "Confidence" SG_ 590 PARK_pscRightCrossSizeX 1;
BA_ "Confidence" SG_ 590 PARK_pscRightCrossSizeY 1;
BA_ "Confidence" SG_ 526 PARK_sdiSensor1RawDistData 1;
BA_ "Confidence" SG_ 526 PARK_sdiSensor2RawDistData 1;
BA_ "Confidence" SG_ 526 PARK_sdiSensor3RawDistData 1;
BA_ "Confidence" SG_ 526 PARK_sdiSensor4RawDistData 1;
BA_ "Confidence" SG_ 526 PARK_sdiSensor5RawDistData 1;
BA_ "Confidence" SG_ 526 PARK_sdiSensor6RawDistData 1;
BA_ "Confidence" SG_ 558 PARK_sdiSensor7RawDistData 1;
BA_ "Confidence" SG_ 558 PARK_sdiSensor8RawDistData 1;
BA_ "Confidence" SG_ 558 PARK_sdiSensor9RawDistData 1;
BA_ "Confidence" SG_ 558 PARK_sdiSensor10RawDistData 1;
BA_ "Confidence" SG_ 558 PARK_sdiSensor11RawDistData 1;
BA_ "Confidence" SG_ 558 PARK_sdiSensor12RawDistData 1;
BA_ "Confidence" SG_ 814 PARK_frontRightSensorState 1;
BA_ "Confidence" SG_ 814 PARK_frontRightMiddleSensorState 1;
BA_ "Confidence" SG_ 814 PARK_frontLeftMiddleSensorState 1;
BA_ "Confidence" SG_ 814 PARK_frontLeftSensorState 1;
BA_ "Confidence" SG_ 814 PARK_frontLeftRawDistData 1;
BA_ "Confidence" SG_ 814 PARK_frontRightRawDistData 1;
BA_ "Confidence" SG_ 814 PARK_systemStatusFront 1;
BA_ "Confidence" SG_ 814 PARK_frontDtcPresent 1;
BA_ "Confidence" SG_ 830 PARK_rearRightSensorState 1;
BA_ "Confidence" SG_ 830 PARK_rearRightMiddleSensorState 1;
BA_ "Confidence" SG_ 830 PARK_rearLeftMiddleSensorState 1;
BA_ "Confidence" SG_ 830 PARK_rearLeftSensorState 1;
BA_ "Confidence" SG_ 830 PARK_rearLeftRawDistData 1;
BA_ "Confidence" SG_ 830 PARK_rearRightRawDistData 1;
BA_ "Confidence" SG_ 830 PARK_systemStatusRear 1;
BA_ "Confidence" SG_ 830 PARK_rearDtcPresent 1;
BA_ "Confidence" SG_ 799 PARK_status 1;
BA_ "Confidence" SG_ 799 PARK_serviceRequest 1;
BA_ "Confidence" SG_ 799 PARK_systemDtcPresent 1;
BA_ "Confidence" SG_ 782 PARK_pscRightCurbType 1;
BA_ "Confidence" SG_ 782 PARK_pscLeftCurbType 1;
BA_ "Confidence" SG_ 782 PARK_autoCalComplete 1;
BA_ "Confidence" SG_ 782 PARK_geometryType 1;
BA_ "Confidence" SG_ 782 PARK_tireFitment 1;
BA_ "Confidence" SG_ 782 PARK_rackDetected 1;
BA_ "Confidence" SG_ 782 PARK_sdiActive 1;
BA_ "Confidence" SG_ 782 PARK_sdiNoise 1;
BA_ "Confidence" SG_ 782 PARK_sdiBlindSpotRight 1;
BA_ "Confidence" SG_ 782 PARK_sdiBlindSpotLeft 1;
BA_ "Confidence" SG_ 782 PARK_sensorType 1;
VAL_ 806 PARK_infoBuildType 4 "INFO_MFG_BUILD" 3 "INFO_TRACEABLE_CI_BUILD" 2 "INFO_LOCAL_BUILD" 1 "INFO_PLATFORM_BUILD" 0 "INFO_UNKNOWN_BUILD" ;
VAL_ 542 PARK_pscParkStatus 6 "FAULT" 5 "GUIDANCE_FINISHED" 4 "PRE_GUIDANCE" 3 "GUIDANCE_RIGHT" 2 "GUIDANCE_LEFT" 1 "SEARCHING" 0 "NOT_AVAILABLE" ;
VAL_ 542 PARK_pscParkAbortReason 25 "PSC_MOVEMENT_AT_ACTIVATION" 24 "PSC_MAX_WAY_BEHIND_HINT" 23 "PSC_PARK_STC_FAILED" 22 "PSC_PARK_PONR_NOT_REACHED" 21 "PSC_VCTL_GENERAL_ABORT" 20 "PSC_HIGH_TORQUE" 19 "PSC_ASYNC_CTRL_SYSTEM" 18 "ERROR" 17 "SYSTEM_SERVICE" 16 "SYSTEM_FAULT" 15 "ECU_INTERNAL_FAULT" 14 "DAS_ABORT" 13 "EPAS_FAULT" 12 "VEHICLE_DYNAMICS_INTERVENTION" 11 "HANDS_ON_DETECTED" 10 "FULL_WARNING_ON_BOTH_SIDES" 9 "PARK_SPACE_TOO_SMALL" 8 "OBSTACLE_ON_PATH" 7 "MAX_YAW_ANGLE_REACHED" 6 "MAX_SWA_DEV_EXCEEDED" 5 "OFF_TRACK" 4 "UNCONTROLLED_TRAVEL_DIST_REACHED" 3 "NO_VALID_PATH" 2 "MAX_NUM_OF_MOVES" 1 "VELOCITY_TOO_HIGH" 0 "NONE" ;
VAL_ 542 PARK_pscParallelSpace 3 "BOTH_AVAILABLE" 2 "LEFT_AVAILABLE" 1 "RIGHT_AVAILABLE" 0 "NONE_AVAILABLE" ;
VAL_ 542 PARK_pscCrossSpace 3 "BOTH_AVAILABLE" 2 "LEFT_AVAILABLE" 1 "RIGHT_AVAILABLE" 0 "NONE_AVAILABLE" ;
VAL_ 542 PARK_pscParallelRightParkable 2 "PARKING_SLOT_OK_POSITION_OK" 1 "PARKING_SLOT_OK" 0 "NONE" ;
VAL_ 542 PARK_pscParallelLeftParkable 2 "PARKING_SLOT_OK_POSITION_OK" 1 "PARKING_SLOT_OK" 0 "NONE" ;
VAL_ 542 PARK_pscCrossRightParkable 2 "PARKING_SLOT_OK_POSITION_OK" 1 "PARKING_SLOT_OK" 0 "NONE" ;
VAL_ 542 PARK_pscCrossLeftParkable 2 "PARKING_SLOT_OK_POSITION_OK" 1 "PARKING_SLOT_OK" 0 "NONE" ;
VAL_ 542 PARK_pscParkInstruction 5 "EXPLORATION" 4 "ABORTED" 3 "DRIVE_BACKWARD" 2 "DRIVE_FORWARD" 1 "STOP" 0 "NO_MESSAGE" ;
VAL_ 542 PARK_pscAngleActive 1 "REQUEST_CONTROL" 0 "INACTIVE" ;
VAL_ 814 PARK_frontRightSensorState 2 "TEMPORARY_FAILURE" 1 "PERMANENT_FAILURE" 0 "NO_FAILURE" ;
VAL_ 814 PARK_frontRightMiddleSensorState 2 "TEMPORARY_FAILURE" 1 "PERMANENT_FAILURE" 0 "NO_FAILURE" ;
VAL_ 814 PARK_frontLeftMiddleSensorState 2 "TEMPORARY_FAILURE" 1 "PERMANENT_FAILURE" 0 "NO_FAILURE" ;
VAL_ 814 PARK_frontLeftSensorState 2 "TEMPORARY_FAILURE" 1 "PERMANENT_FAILURE" 0 "NO_FAILURE" ;
VAL_ 814 PARK_systemStatusFront 2 "UNUSED" 1 "ENABLED" 0 "DISABLED" ;
VAL_ 814 PARK_frontDtcPresent 2 "UNUSED" 1 "TRUE" 0 "FALSE" ;
VAL_ 830 PARK_rearRightSensorState 2 "TEMPORARY_FAILURE" 1 "PERMANENT_FAILURE" 0 "NO_FAILURE" ;
VAL_ 830 PARK_rearRightMiddleSensorState 2 "TEMPORARY_FAILURE" 1 "PERMANENT_FAILURE" 0 "NO_FAILURE" ;
VAL_ 830 PARK_rearLeftMiddleSensorState 2 "TEMPORARY_FAILURE" 1 "PERMANENT_FAILURE" 0 "NO_FAILURE" ;
VAL_ 830 PARK_rearLeftSensorState 2 "TEMPORARY_FAILURE" 1 "PERMANENT_FAILURE" 0 "NO_FAILURE" ;
VAL_ 830 PARK_systemStatusRear 2 "UNUSED" 1 "ENABLED" 0 "DISABLED" ;
VAL_ 830 PARK_rearDtcPresent 2 "UNUSED" 1 "TRUE" 0 "FALSE" ;
VAL_ 799 PARK_status 2 "TEMPORARY_FAILURE" 1 "ENABLED" 0 "DISABLED" ;
VAL_ 799 PARK_serviceRequest 2 "UNUSED" 1 "FAILURE" 0 "NO_FAILURE" ;
VAL_ 799 PARK_systemDtcPresent 2 "UNUSED" 1 "TRUE" 0 "FALSE" ;
VAL_ 782 PARK_pscRightCurbType 2 "HIGH_CURB" 1 "LOW_CURB" 0 "VIRTUAL_CURB" ;
VAL_ 782 PARK_pscLeftCurbType 2 "HIGH_CURB" 1 "LOW_CURB" 0 "VIRTUAL_CURB" ;
VAL_ 782 PARK_autoCalComplete 1 "COMPLETE" 0 "INCOMPLETE" ;
VAL_ 782 PARK_geometryType 3 "MODELY" 2 "MODEL3" 1 "MODELX" 0 "MODELS" ;
VAL_ 782 PARK_tireFitment 2 "NOT_USED" 1 "STAGGERED" 0 "SQUARE" ;
VAL_ 782 PARK_rackDetected 2 "RACK_DETECTED" 1 "NO_RACK" 0 "UNKNOWN" ;
VAL_ 782 PARK_sdiActive 1 "SDI_ENABLED" 0 "SDI_DISABLED" ;
VAL_ 782 PARK_sdiNoise 3 "SDI_NOISE_SNA" 2 "SDI_NOISE_RAIN" 1 "SDI_NOISE_HIGH" 0 "SDI_NOISE_NOMINAL" ;
VAL_ 782 PARK_sdiBlindSpotRight 2 "UNUSED" 1 "WARNING" 0 "NO_WARNING" ;
VAL_ 782 PARK_sdiBlindSpotLeft 2 "UNUSED" 1 "WARNING" 0 "NO_WARNING" ;
VAL_ 782 PARK_sensorType 2 "VALEO_HP" 1 "VALEO_HPFL" 0 "NONE" ;
